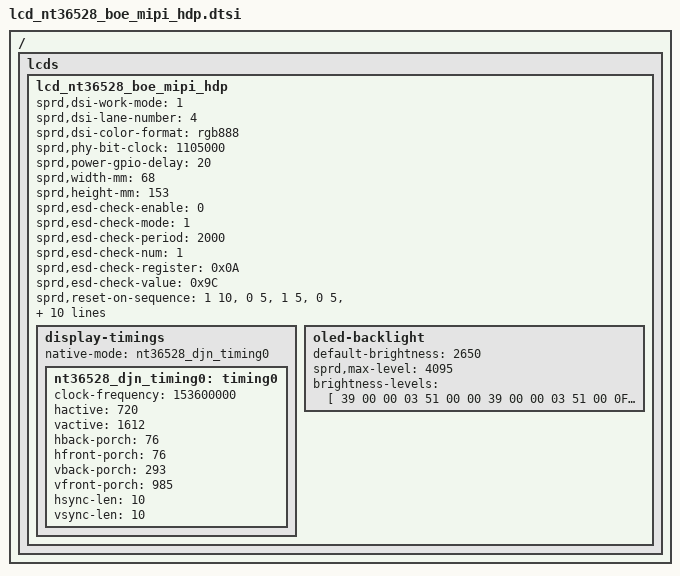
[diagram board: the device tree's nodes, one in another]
// SPDX-License-Identifier: GPL-2.0-only
/*
 * Unisoc ili9881c Truly LCD config DTS file
 *
 * Copyright (C) 2021, Unisoc Inc.
 */
/ {
	fragment {
		target-path = "/";
		__overlay__ {
			lcds {
				lcd_nt36528_boe_mipi_hdp: lcd_nt36528_boe_mipi_hdp {
					sprd,dsi-work-mode = <1>; /* video burst mode*/
					sprd,dsi-lane-number = <4>;
					sprd,dsi-color-format = "rgb888";

					sprd,phy-bit-clock = <1105000>; /* kbps */
					//sprd,phy-escape-clock = <20000>;/* kHz */
					//sprd,dpi-clk-div = <1>;
					sprd,power-gpio-delay = <20>;/* ms */

					//sprd,lcm_ic_name = "NT36528";
					//sprd,lcm_ic_vendor = "DJN";
					//sprd,lcm_ic_inch = "6.56";

					sprd,width-mm = <68>;
					sprd,height-mm = <153>;

					sprd,esd-check-enable = <0>;
					sprd,esd-check-mode = <1>;
					sprd,esd-check-period = <2000>;
					sprd,esd-check-num = <1>;
					sprd,esd-check-register = <0x0A>;
					sprd,esd-check-value = <0x9C>;

					sprd,reset-on-sequence = <1 10>, <0 5>, <1 5>, <0 5>, <1 20>;
					sprd,reset-off-sequence = <1 5>;

					sprd,initial-command = [
						23 00 00 02 FF 20
						23 00 00 02 FB 01
						23 00 00 02 07 B4
						23 00 00 02 08 B4
						23 00 00 02 0D 80
						23 00 00 02 1F 22
						23 00 00 02 82 66
						23 00 00 02 89 BE
						23 00 00 02 8B BE
						23 00 00 02 94 C0
						23 00 00 02 95 13
						23 00 00 02 96 13
						23 00 00 02 FF 24
						23 00 00 02 FB 01
						23 00 00 02 01 26
						23 00 00 02 02 21
						23 00 00 02 03 04
						23 00 00 02 04 05
						23 00 00 02 05 0C
						23 00 00 02 06 0D
						23 00 00 02 07 0E
						23 00 00 02 08 0F
						23 00 00 02 09 10
						23 00 00 02 0A 11
						23 00 00 02 0B 12
						23 00 00 02 0C 13
						23 00 00 02 0D 20
						23 00 00 02 17 26
						23 00 00 02 18 21
						23 00 00 02 19 04
						23 00 00 02 1A 05
						23 00 00 02 1B 0C
						23 00 00 02 1C 0D
						23 00 00 02 1D 0E
						23 00 00 02 1E 0F
						23 00 00 02 1F 10
						23 00 00 02 20 11
						23 00 00 02 21 12
						23 00 00 02 22 13
						23 00 00 02 23 20
						23 00 00 02 2F 11
						23 00 00 02 30 0D
						23 00 00 02 33 0D
						23 00 00 02 34 11
						23 00 00 02 37 88
						23 00 00 02 3A 06
						23 00 00 02 3B C8
						23 00 00 02 3D 52
						23 00 00 02 50 87
						23 00 00 02 51 78
						23 00 00 02 52 56
						23 00 00 02 53 34
						23 00 00 02 54 12
						39 00 00 03 55 4E 0E
						23 00 00 02 56 08
						23 00 00 02 5C 8A
						23 00 00 02 5D 0A
						39 00 00 03 5E 00 08
						23 00 00 02 AF 12
						23 00 00 02 B0 09
						23 00 00 02 B1 12
						23 00 00 02 B2 09
						23 00 00 02 FF 25
						23 00 00 02 FB 01
						23 00 00 02 44 06
						23 00 00 02 5D 06
						23 00 00 02 5E C8
						23 00 00 02 C0 8C
						23 00 00 02 C6 11
						23 00 00 02 FF 26
						23 00 00 02 FB 01
						23 00 00 02 4D 06
						23 00 00 02 4E 78
						23 00 00 02 6E 06
						23 00 00 02 6F 78
						23 00 00 02 7B 06
						23 00 00 02 7C 78
						23 00 00 02 FF 27
						23 00 00 02 FB 01
						23 00 00 02 14 66
						23 00 00 02 15 D8
						23 00 00 02 1A 66
						23 00 00 02 1B 66
						23 00 00 02 78 98
						23 00 00 02 79 0F
						23 00 00 02 7A 0F
						23 00 00 02 7C 0A
						23 00 00 02 7D 69
						23 00 00 02 7E 0A
						23 00 00 02 7F 69
						23 00 00 02 80 0A
						23 00 00 02 81 69
						23 00 00 02 83 12
						23 00 00 02 84 0E
						23 00 00 02 87 0E
						23 00 00 02 88 12
						23 00 00 02 93 80
						23 00 00 02 94 80
						23 00 00 02 96 0B
						23 00 00 02 97 15
						23 00 00 02 98 88
						23 00 00 02 C4 06
						23 00 00 02 C5 78
						23 00 00 02 C6 06
						23 00 00 02 C7 78
						23 00 00 02 E4 00
						23 00 00 02 E5 9D
						23 00 00 02 FF 2A
						23 00 00 02 FB 01
						23 00 00 02 64 96
						23 00 00 02 67 16
						23 00 00 02 6A 96
						23 00 00 02 73 9E
						23 00 00 02 76 9E
						23 00 00 02 79 16
						23 00 00 02 7C 16
						23 00 00 02 7F 96
						23 00 00 02 82 16
						23 00 00 02 85 16
						23 00 00 02 A2 3F
						23 00 00 02 A3 FF
						23 00 00 02 A4 C3
						23 00 00 02 FF 24
						23 00 00 02 FB 01
						23 00 00 02 59 70
						23 00 00 02 5A BC
						23 00 00 02 5B AA
						23 00 00 02 61 4C
						23 00 00 02 92 CE
						39 00 00 03 93 12 00
						23 00 00 02 94 C8
						23 00 00 02 DC C9
						23 00 00 02 E0 C9
						23 00 00 02 E2 C9
						23 00 00 02 E4 C9
						23 00 00 02 E6 C9
						23 00 00 02 EA C9
						23 00 00 02 EE C9
						23 00 00 02 F0 C9
						23 00 00 02 FF 25
						23 00 00 02 FB 01
						23 00 00 02 13 02
						23 00 00 02 14 72
						23 00 00 02 15 01
						23 00 00 02 16 8B
						23 00 00 02 1F BC
						23 00 00 02 20 AA
						23 00 00 02 26 BC
						23 00 00 02 27 AA
						23 00 00 02 48 BC
						23 00 00 02 49 AA
						23 00 00 02 50 BC
						23 00 00 02 51 AA
						23 00 00 02 61 BC
						23 00 00 02 62 AA
						23 00 00 02 68 08
						23 00 00 02 BC 24
						23 00 00 02 FF 26
						23 00 00 02 FB 01
						23 00 00 02 00 80
						23 00 00 02 02 0D
						23 00 00 02 04 2F
						23 00 00 02 09 05
						23 00 00 02 0A 05
						23 00 00 02 19 0B
						23 00 00 02 1A 54
						23 00 00 02 1B 0A
						23 00 00 02 1C C9
						23 00 00 02 1E CE
						23 00 00 02 1F CE
						23 00 00 02 24 00
						23 00 00 02 25 CE
						23 00 00 02 2A 0B
						23 00 00 02 2B 54
						23 00 00 02 2F 05
						23 00 00 02 30 CE
						23 00 00 02 32 CE
						23 00 00 02 37 11
						23 00 00 02 38 01
						23 00 00 02 39 08
						23 00 00 02 3A CE
						23 00 00 02 40 81
						23 00 00 02 41 81
						23 00 00 02 42 81
						23 00 00 02 44 81
						23 00 00 02 46 81
						23 00 00 02 48 81
						23 00 00 02 49 08
						23 00 00 02 4A 81
						23 00 00 02 51 7B
						23 00 00 02 52 69
						23 00 00 02 56 7B
						23 00 00 02 58 69
						23 00 00 02 5B 7B
						23 00 00 02 5C 69
						23 00 00 02 60 7B
						23 00 00 02 61 69
						23 00 00 02 64 7B
						23 00 00 02 65 69
						23 00 00 02 69 7B
						23 00 00 02 6A 69
						23 00 00 02 72 7B
						23 00 00 02 73 69
						23 00 00 02 8B 35
						23 00 00 02 8C 09
						23 00 00 02 8D 00
						23 00 00 02 99 0B
						23 00 00 02 9A 54
						23 00 00 02 9B 0A
						23 00 00 02 9C C9
						23 00 00 02 9D 0B
						23 00 00 02 9E 54
						23 00 00 02 C3 00
						23 00 00 02 FF 27
						23 00 00 02 FB 01
						23 00 00 02 58 A4
						39 00 00 03 59 00 12
						39 00 00 03 5A 00 C3
						39 00 00 03 5D 00 01
						39 00 00 03 5E 00 B1
						23 00 00 02 5F 01
						39 00 00 03 60 06 75
						23 00 00 02 C0 08
						23 00 00 02 F0 77
						23 00 00 02 F1 10
						23 00 00 02 F4 00
						23 00 00 02 F5 77
						23 00 00 02 FF 2A
						23 00 00 02 FB 01
						23 00 00 02 04 7C
						23 00 00 02 06 7C
						23 00 00 02 09 7C
						23 00 00 02 0B 7C
						23 00 00 02 0D 7C
						23 00 00 02 14 7C
						23 00 00 02 15 7C
						23 00 00 02 16 7C
						23 00 00 02 23 0C
						23 00 00 02 28 12
						23 00 00 02 2D 12
						23 00 00 02 33 12
						23 00 00 02 35 0A
						23 00 00 02 37 79
						23 00 00 02 99 95
						23 00 00 02 9A 0B
						23 00 00 02 C4 80
						23 00 00 02 C5 12
						23 00 00 02 C6 01
						23 00 00 02 C7 2A
						23 00 00 02 C8 10
						23 00 00 02 C9 01
						23 00 00 02 CA 18
						23 00 00 02 CB 16
						23 00 00 02 CC 75
						23 00 00 02 FF 23
						23 00 00 02 FB 01
						23 00 00 02 00 80
						23 00 00 02 07 00
						23 00 00 02 08 01
						23 00 00 02 09 1F
						23 00 00 02 11 00
						23 00 00 02 12 B5
						23 00 00 02 15 E7
						23 00 00 02 16 14
						23 00 00 02 FF 25
						23 00 00 02 FB 01
						39 00 00 05 02 00 40 00 40
						23 00 00 02 FF 27
						23 00 00 02 FB 01
						23 00 00 02 E9 02
						23 00 00 02 FF 2A
						23 00 00 02 FB 01
						23 00 00 02 99 95
						23 00 00 02 9A 0B
						23 00 00 02 AC 00
						23 00 00 02 AD 3C
						23 00 00 02 AE 80
						23 00 00 02 AF 43
						23 00 00 02 B0 18
						23 00 00 02 B1 90
						23 00 00 02 B3 22
						23 00 00 02 FF 10
						23 00 00 02 FB 01
						23 00 00 02 BA 03
						23 00 00 02 FF 25
						23 00 00 02 FB 01
						23 00 00 02 BC 24
						23 00 00 02 FF 26
						23 00 00 02 FB 01
						23 00 00 02 09 05
						23 00 00 02 FF 2A
						23 00 00 02 FB 01
						23 00 00 02 23 0C
						23 00 00 02 FF 10
						23 00 00 02 FB 01
						23 00 00 02 55 00
						23 00 00 02 53 2C
						39 00 00 03 51 00 00
						23 00 00 02 35 00
						13 78 00 01 11
						13 14 00 01 29
						];

					sprd,sleep-in-command = [
						13 14 00 01 28
						13 78 00 01 10
						];

					sprd,sleep-out-command = [
						13 78 00 01 11
						13 14 00 01 29
						];

					sprd,oled-backlight-close = [
						39 00 00 03 51 00 00
						];

					display-timings {
						native-mode = <&nt36528_djn_timing0>;

						nt36528_djn_timing0: timing0 {
							clock-frequency = <153600000>;
							hactive = <720>;
							vactive = <1612>;
							hback-porch = <76>;
							hfront-porch = <76>;
							vback-porch = <293>;
							vfront-porch = <985>;
							hsync-len = <10>;
							vsync-len = <10>;
						};
						//nt36528_djn_timing1: timing1 {
						//	clock-frequency = <153600000>;
						//	hactive = <720>;
						//	vactive = <1612>;
						//	hback-porch = <76>;
						//	hfront-porch = <76>;
						//	vback-porch = <293>;
						//	vfront-porch = <18>;
						//	hsync-len = <10>;
						//	vsync-len = <10>;
						//};
					};

					oled-backlight {
						default-brightness = <2650>;
						sprd,max-level = <4095>;

						brightness-levels = [
							39 00 00 03 51 00 00
							39 00 00 03 51 00 0F
							39 00 00 03 51 00 0F
							39 00 00 03 51 00 0F
							39 00 00 03 51 00 0F
							39 00 00 03 51 00 0F
							39 00 00 03 51 00 0F
							39 00 00 03 51 00 0F
							39 00 00 03 51 00 0F
							39 00 00 03 51 00 0F
							39 00 00 03 51 00 0F
							39 00 00 03 51 00 0F
							39 00 00 03 51 00 0F
							39 00 00 03 51 00 0F
							39 00 00 03 51 00 0F
							39 00 00 03 51 00 0F
							39 00 00 03 51 00 10
							39 00 00 03 51 00 11
							39 00 00 03 51 00 12
							39 00 00 03 51 00 13
							39 00 00 03 51 00 14
							39 00 00 03 51 00 15
							39 00 00 03 51 00 16
							39 00 00 03 51 00 17
							39 00 00 03 51 00 18
							39 00 00 03 51 00 19
							39 00 00 03 51 00 1A
							39 00 00 03 51 00 1B
							39 00 00 03 51 00 1C
							39 00 00 03 51 00 1D
							39 00 00 03 51 00 1E
							39 00 00 03 51 00 1F
							39 00 00 03 51 00 20
							39 00 00 03 51 00 21
							39 00 00 03 51 00 22
							39 00 00 03 51 00 23
							39 00 00 03 51 00 24
							39 00 00 03 51 00 25
							39 00 00 03 51 00 26
							39 00 00 03 51 00 27
							39 00 00 03 51 00 28
							39 00 00 03 51 00 29
							39 00 00 03 51 00 2A
							39 00 00 03 51 00 2B
							39 00 00 03 51 00 2C
							39 00 00 03 51 00 2D
							39 00 00 03 51 00 2E
							39 00 00 03 51 00 2F
							39 00 00 03 51 00 30
							39 00 00 03 51 00 31
							39 00 00 03 51 00 32
							39 00 00 03 51 00 33
							39 00 00 03 51 00 34
							39 00 00 03 51 00 35
							39 00 00 03 51 00 36
							39 00 00 03 51 00 37
							39 00 00 03 51 00 38
							39 00 00 03 51 00 39
							39 00 00 03 51 00 3A
							39 00 00 03 51 00 3B
							39 00 00 03 51 00 3C
							39 00 00 03 51 00 3D
							39 00 00 03 51 00 3E
							39 00 00 03 51 00 3F
							39 00 00 03 51 00 40
							39 00 00 03 51 00 41
							39 00 00 03 51 00 42
							39 00 00 03 51 00 43
							39 00 00 03 51 00 44
							39 00 00 03 51 00 45
							39 00 00 03 51 00 46
							39 00 00 03 51 00 47
							39 00 00 03 51 00 48
							39 00 00 03 51 00 49
							39 00 00 03 51 00 4A
							39 00 00 03 51 00 4B
							39 00 00 03 51 00 4C
							39 00 00 03 51 00 4D
							39 00 00 03 51 00 4E
							39 00 00 03 51 00 4F
							39 00 00 03 51 00 50
							39 00 00 03 51 00 51
							39 00 00 03 51 00 52
							39 00 00 03 51 00 53
							39 00 00 03 51 00 54
							39 00 00 03 51 00 55
							39 00 00 03 51 00 56
							39 00 00 03 51 00 57
							39 00 00 03 51 00 58
							39 00 00 03 51 00 59
							39 00 00 03 51 00 5A
							39 00 00 03 51 00 5B
							39 00 00 03 51 00 5C
							39 00 00 03 51 00 5D
							39 00 00 03 51 00 5E
							39 00 00 03 51 00 5F
							39 00 00 03 51 00 60
							39 00 00 03 51 00 61
							39 00 00 03 51 00 62
							39 00 00 03 51 00 63
							39 00 00 03 51 00 64
							39 00 00 03 51 00 65
							39 00 00 03 51 00 66
							39 00 00 03 51 00 67
							39 00 00 03 51 00 68
							39 00 00 03 51 00 69
							39 00 00 03 51 00 6A
							39 00 00 03 51 00 6B
							39 00 00 03 51 00 6C
							39 00 00 03 51 00 6D
							39 00 00 03 51 00 6E
							39 00 00 03 51 00 6F
							39 00 00 03 51 00 70
							39 00 00 03 51 00 71
							39 00 00 03 51 00 72
							39 00 00 03 51 00 73
							39 00 00 03 51 00 74
							39 00 00 03 51 00 75
							39 00 00 03 51 00 76
							39 00 00 03 51 00 77
							39 00 00 03 51 00 78
							39 00 00 03 51 00 79
							39 00 00 03 51 00 7A
							39 00 00 03 51 00 7B
							39 00 00 03 51 00 7C
							39 00 00 03 51 00 7D
							39 00 00 03 51 00 7E
							39 00 00 03 51 00 7F
							39 00 00 03 51 00 80
							39 00 00 03 51 00 81
							39 00 00 03 51 00 82
							39 00 00 03 51 00 83
							39 00 00 03 51 00 84
							39 00 00 03 51 00 85
							39 00 00 03 51 00 86
							39 00 00 03 51 00 87
							39 00 00 03 51 00 88
							39 00 00 03 51 00 89
							39 00 00 03 51 00 8A
							39 00 00 03 51 00 8B
							39 00 00 03 51 00 8C
							39 00 00 03 51 00 8D
							39 00 00 03 51 00 8E
							39 00 00 03 51 00 8F
							39 00 00 03 51 00 90
							39 00 00 03 51 00 91
							39 00 00 03 51 00 92
							39 00 00 03 51 00 93
							39 00 00 03 51 00 94
							39 00 00 03 51 00 95
							39 00 00 03 51 00 96
							39 00 00 03 51 00 97
							39 00 00 03 51 00 98
							39 00 00 03 51 00 99
							39 00 00 03 51 00 9A
							39 00 00 03 51 00 9B
							39 00 00 03 51 00 9C
							39 00 00 03 51 00 9D
							39 00 00 03 51 00 9E
							39 00 00 03 51 00 9F
							39 00 00 03 51 00 A0
							39 00 00 03 51 00 A1
							39 00 00 03 51 00 A2
							39 00 00 03 51 00 A3
							39 00 00 03 51 00 A4
							39 00 00 03 51 00 A5
							39 00 00 03 51 00 A6
							39 00 00 03 51 00 A7
							39 00 00 03 51 00 A8
							39 00 00 03 51 00 A9
							39 00 00 03 51 00 AA
							39 00 00 03 51 00 AB
							39 00 00 03 51 00 AC
							39 00 00 03 51 00 AD
							39 00 00 03 51 00 AE
							39 00 00 03 51 00 AF
							39 00 00 03 51 00 B0
							39 00 00 03 51 00 B1
							39 00 00 03 51 00 B2
							39 00 00 03 51 00 B3
							39 00 00 03 51 00 B4
							39 00 00 03 51 00 B5
							39 00 00 03 51 00 B6
							39 00 00 03 51 00 B7
							39 00 00 03 51 00 B8
							39 00 00 03 51 00 B9
							39 00 00 03 51 00 BA
							39 00 00 03 51 00 BB
							39 00 00 03 51 00 BC
							39 00 00 03 51 00 BD
							39 00 00 03 51 00 BE
							39 00 00 03 51 00 BF
							39 00 00 03 51 00 C0
							39 00 00 03 51 00 C1
							39 00 00 03 51 00 C2
							39 00 00 03 51 00 C3
							39 00 00 03 51 00 C4
							39 00 00 03 51 00 C5
							39 00 00 03 51 00 C6
							39 00 00 03 51 00 C7
							39 00 00 03 51 00 C8
							39 00 00 03 51 00 C9
							39 00 00 03 51 00 CA
							39 00 00 03 51 00 CB
							39 00 00 03 51 00 CC
							39 00 00 03 51 00 CD
							39 00 00 03 51 00 CE
							39 00 00 03 51 00 CF
							39 00 00 03 51 00 D0
							39 00 00 03 51 00 D1
							39 00 00 03 51 00 D2
							39 00 00 03 51 00 D3
							39 00 00 03 51 00 D4
							39 00 00 03 51 00 D5
							39 00 00 03 51 00 D6
							39 00 00 03 51 00 D7
							39 00 00 03 51 00 D8
							39 00 00 03 51 00 D9
							39 00 00 03 51 00 DA
							39 00 00 03 51 00 DB
							39 00 00 03 51 00 DC
							39 00 00 03 51 00 DD
							39 00 00 03 51 00 DE
							39 00 00 03 51 00 DF
							39 00 00 03 51 00 E0
							39 00 00 03 51 00 E1
							39 00 00 03 51 00 E2
							39 00 00 03 51 00 E3
							39 00 00 03 51 00 E4
							39 00 00 03 51 00 E5
							39 00 00 03 51 00 E6
							39 00 00 03 51 00 E7
							39 00 00 03 51 00 E8
							39 00 00 03 51 00 E9
							39 00 00 03 51 00 EA
							39 00 00 03 51 00 EB
							39 00 00 03 51 00 EC
							39 00 00 03 51 00 ED
							39 00 00 03 51 00 EE
							39 00 00 03 51 00 EF
							39 00 00 03 51 00 F0
							39 00 00 03 51 00 F1
							39 00 00 03 51 00 F2
							39 00 00 03 51 00 F3
							39 00 00 03 51 00 F4
							39 00 00 03 51 00 F5
							39 00 00 03 51 00 F6
							39 00 00 03 51 00 F7
							39 00 00 03 51 00 F8
							39 00 00 03 51 00 F9
							39 00 00 03 51 00 FA
							39 00 00 03 51 00 FB
							39 00 00 03 51 00 FC
							39 00 00 03 51 00 FD
							39 00 00 03 51 00 FE
							39 00 00 03 51 00 FF
							39 00 00 03 51 01 00
							39 00 00 03 51 01 01
							39 00 00 03 51 01 02
							39 00 00 03 51 01 03
							39 00 00 03 51 01 04
							39 00 00 03 51 01 05
							39 00 00 03 51 01 06
							39 00 00 03 51 01 07
							39 00 00 03 51 01 08
							39 00 00 03 51 01 09
							39 00 00 03 51 01 0A
							39 00 00 03 51 01 0B
							39 00 00 03 51 01 0C
							39 00 00 03 51 01 0D
							39 00 00 03 51 01 0E
							39 00 00 03 51 01 0F
							39 00 00 03 51 01 10
							39 00 00 03 51 01 11
							39 00 00 03 51 01 12
							39 00 00 03 51 01 13
							39 00 00 03 51 01 14
							39 00 00 03 51 01 15
							39 00 00 03 51 01 16
							39 00 00 03 51 01 17
							39 00 00 03 51 01 18
							39 00 00 03 51 01 19
							39 00 00 03 51 01 1A
							39 00 00 03 51 01 1B
							39 00 00 03 51 01 1C
							39 00 00 03 51 01 1D
							39 00 00 03 51 01 1E
							39 00 00 03 51 01 1F
							39 00 00 03 51 01 20
							39 00 00 03 51 01 21
							39 00 00 03 51 01 22
							39 00 00 03 51 01 23
							39 00 00 03 51 01 24
							39 00 00 03 51 01 25
							39 00 00 03 51 01 26
							39 00 00 03 51 01 27
							39 00 00 03 51 01 28
							39 00 00 03 51 01 29
							39 00 00 03 51 01 2A
							39 00 00 03 51 01 2B
							39 00 00 03 51 01 2C
							39 00 00 03 51 01 2D
							39 00 00 03 51 01 2E
							39 00 00 03 51 01 2F
							39 00 00 03 51 01 30
							39 00 00 03 51 01 31
							39 00 00 03 51 01 32
							39 00 00 03 51 01 33
							39 00 00 03 51 01 34
							39 00 00 03 51 01 35
							39 00 00 03 51 01 36
							39 00 00 03 51 01 37
							39 00 00 03 51 01 38
							39 00 00 03 51 01 39
							39 00 00 03 51 01 3A
							39 00 00 03 51 01 3B
							39 00 00 03 51 01 3C
							39 00 00 03 51 01 3D
							39 00 00 03 51 01 3E
							39 00 00 03 51 01 3F
							39 00 00 03 51 01 40
							39 00 00 03 51 01 41
							39 00 00 03 51 01 42
							39 00 00 03 51 01 43
							39 00 00 03 51 01 44
							39 00 00 03 51 01 45
							39 00 00 03 51 01 46
							39 00 00 03 51 01 47
							39 00 00 03 51 01 48
							39 00 00 03 51 01 49
							39 00 00 03 51 01 4A
							39 00 00 03 51 01 4B
							39 00 00 03 51 01 4C
							39 00 00 03 51 01 4D
							39 00 00 03 51 01 4E
							39 00 00 03 51 01 4F
							39 00 00 03 51 01 50
							39 00 00 03 51 01 51
							39 00 00 03 51 01 52
							39 00 00 03 51 01 53
							39 00 00 03 51 01 54
							39 00 00 03 51 01 55
							39 00 00 03 51 01 56
							39 00 00 03 51 01 57
							39 00 00 03 51 01 58
							39 00 00 03 51 01 59
							39 00 00 03 51 01 5A
							39 00 00 03 51 01 5B
							39 00 00 03 51 01 5C
							39 00 00 03 51 01 5D
							39 00 00 03 51 01 5E
							39 00 00 03 51 01 5F
							39 00 00 03 51 01 60
							39 00 00 03 51 01 61
							39 00 00 03 51 01 62
							39 00 00 03 51 01 63
							39 00 00 03 51 01 64
							39 00 00 03 51 01 65
							39 00 00 03 51 01 66
							39 00 00 03 51 01 67
							39 00 00 03 51 01 68
							39 00 00 03 51 01 69
							39 00 00 03 51 01 6A
							39 00 00 03 51 01 6B
							39 00 00 03 51 01 6C
							39 00 00 03 51 01 6D
							39 00 00 03 51 01 6E
							39 00 00 03 51 01 6F
							39 00 00 03 51 01 70
							39 00 00 03 51 01 71
							39 00 00 03 51 01 72
							39 00 00 03 51 01 73
							39 00 00 03 51 01 74
							39 00 00 03 51 01 75
							39 00 00 03 51 01 76
							39 00 00 03 51 01 77
							39 00 00 03 51 01 78
							39 00 00 03 51 01 79
							39 00 00 03 51 01 7A
							39 00 00 03 51 01 7B
							39 00 00 03 51 01 7C
							39 00 00 03 51 01 7D
							39 00 00 03 51 01 7E
							39 00 00 03 51 01 7F
							39 00 00 03 51 01 80
							39 00 00 03 51 01 81
							39 00 00 03 51 01 82
							39 00 00 03 51 01 83
							39 00 00 03 51 01 84
							39 00 00 03 51 01 85
							39 00 00 03 51 01 86
							39 00 00 03 51 01 87
							39 00 00 03 51 01 88
							39 00 00 03 51 01 89
							39 00 00 03 51 01 8A
							39 00 00 03 51 01 8B
							39 00 00 03 51 01 8C
							39 00 00 03 51 01 8D
							39 00 00 03 51 01 8E
							39 00 00 03 51 01 8F
							39 00 00 03 51 01 90
							39 00 00 03 51 01 91
							39 00 00 03 51 01 92
							39 00 00 03 51 01 93
							39 00 00 03 51 01 94
							39 00 00 03 51 01 95
							39 00 00 03 51 01 96
							39 00 00 03 51 01 97
							39 00 00 03 51 01 98
							39 00 00 03 51 01 99
							39 00 00 03 51 01 9A
							39 00 00 03 51 01 9B
							39 00 00 03 51 01 9C
							39 00 00 03 51 01 9D
							39 00 00 03 51 01 9E
							39 00 00 03 51 01 9F
							39 00 00 03 51 01 A0
							39 00 00 03 51 01 A1
							39 00 00 03 51 01 A2
							39 00 00 03 51 01 A3
							39 00 00 03 51 01 A4
							39 00 00 03 51 01 A5
							39 00 00 03 51 01 A6
							39 00 00 03 51 01 A7
							39 00 00 03 51 01 A8
							39 00 00 03 51 01 A9
							39 00 00 03 51 01 AA
							39 00 00 03 51 01 AB
							39 00 00 03 51 01 AC
							39 00 00 03 51 01 AD
							39 00 00 03 51 01 AE
							39 00 00 03 51 01 AF
							39 00 00 03 51 01 B0
							39 00 00 03 51 01 B1
							39 00 00 03 51 01 B2
							39 00 00 03 51 01 B3
							39 00 00 03 51 01 B4
							39 00 00 03 51 01 B5
							39 00 00 03 51 01 B6
							39 00 00 03 51 01 B7
							39 00 00 03 51 01 B8
							39 00 00 03 51 01 B9
							39 00 00 03 51 01 BA
							39 00 00 03 51 01 BB
							39 00 00 03 51 01 BC
							39 00 00 03 51 01 BD
							39 00 00 03 51 01 BE
							39 00 00 03 51 01 BF
							39 00 00 03 51 01 C0
							39 00 00 03 51 01 C1
							39 00 00 03 51 01 C2
							39 00 00 03 51 01 C3
							39 00 00 03 51 01 C4
							39 00 00 03 51 01 C5
							39 00 00 03 51 01 C6
							39 00 00 03 51 01 C7
							39 00 00 03 51 01 C8
							39 00 00 03 51 01 C9
							39 00 00 03 51 01 CA
							39 00 00 03 51 01 CB
							39 00 00 03 51 01 CC
							39 00 00 03 51 01 CD
							39 00 00 03 51 01 CE
							39 00 00 03 51 01 CF
							39 00 00 03 51 01 D0
							39 00 00 03 51 01 D1
							39 00 00 03 51 01 D2
							39 00 00 03 51 01 D3
							39 00 00 03 51 01 D4
							39 00 00 03 51 01 D5
							39 00 00 03 51 01 D6
							39 00 00 03 51 01 D7
							39 00 00 03 51 01 D8
							39 00 00 03 51 01 D9
							39 00 00 03 51 01 DA
							39 00 00 03 51 01 DB
							39 00 00 03 51 01 DC
							39 00 00 03 51 01 DD
							39 00 00 03 51 01 DE
							39 00 00 03 51 01 DF
							39 00 00 03 51 01 E0
							39 00 00 03 51 01 E1
							39 00 00 03 51 01 E2
							39 00 00 03 51 01 E3
							39 00 00 03 51 01 E4
							39 00 00 03 51 01 E5
							39 00 00 03 51 01 E6
							39 00 00 03 51 01 E7
							39 00 00 03 51 01 E8
							39 00 00 03 51 01 E9
							39 00 00 03 51 01 EA
							39 00 00 03 51 01 EB
							39 00 00 03 51 01 EC
							39 00 00 03 51 01 ED
							39 00 00 03 51 01 EE
							39 00 00 03 51 01 EF
							39 00 00 03 51 01 F0
							39 00 00 03 51 01 F1
							39 00 00 03 51 01 F2
							39 00 00 03 51 01 F3
							39 00 00 03 51 01 F4
							39 00 00 03 51 01 F5
							39 00 00 03 51 01 F6
							39 00 00 03 51 01 F7
							39 00 00 03 51 01 F8
							39 00 00 03 51 01 F9
							39 00 00 03 51 01 FA
							39 00 00 03 51 01 FB
							39 00 00 03 51 01 FC
							39 00 00 03 51 01 FD
							39 00 00 03 51 01 FE
							39 00 00 03 51 01 FF
							39 00 00 03 51 02 00
							39 00 00 03 51 02 01
							39 00 00 03 51 02 02
							39 00 00 03 51 02 03
							39 00 00 03 51 02 04
							39 00 00 03 51 02 05
							39 00 00 03 51 02 06
							39 00 00 03 51 02 07
							39 00 00 03 51 02 08
							39 00 00 03 51 02 09
							39 00 00 03 51 02 0A
							39 00 00 03 51 02 0B
							39 00 00 03 51 02 0C
							39 00 00 03 51 02 0D
							39 00 00 03 51 02 0E
							39 00 00 03 51 02 0F
							39 00 00 03 51 02 10
							39 00 00 03 51 02 11
							39 00 00 03 51 02 12
							39 00 00 03 51 02 13
							39 00 00 03 51 02 14
							39 00 00 03 51 02 15
							39 00 00 03 51 02 16
							39 00 00 03 51 02 17
							39 00 00 03 51 02 18
							39 00 00 03 51 02 19
							39 00 00 03 51 02 1A
							39 00 00 03 51 02 1B
							39 00 00 03 51 02 1C
							39 00 00 03 51 02 1D
							39 00 00 03 51 02 1E
							39 00 00 03 51 02 1F
							39 00 00 03 51 02 20
							39 00 00 03 51 02 21
							39 00 00 03 51 02 22
							39 00 00 03 51 02 23
							39 00 00 03 51 02 24
							39 00 00 03 51 02 25
							39 00 00 03 51 02 26
							39 00 00 03 51 02 27
							39 00 00 03 51 02 28
							39 00 00 03 51 02 29
							39 00 00 03 51 02 2A
							39 00 00 03 51 02 2B
							39 00 00 03 51 02 2C
							39 00 00 03 51 02 2D
							39 00 00 03 51 02 2E
							39 00 00 03 51 02 2F
							39 00 00 03 51 02 30
							39 00 00 03 51 02 31
							39 00 00 03 51 02 32
							39 00 00 03 51 02 33
							39 00 00 03 51 02 34
							39 00 00 03 51 02 35
							39 00 00 03 51 02 36
							39 00 00 03 51 02 37
							39 00 00 03 51 02 38
							39 00 00 03 51 02 39
							39 00 00 03 51 02 3A
							39 00 00 03 51 02 3B
							39 00 00 03 51 02 3C
							39 00 00 03 51 02 3D
							39 00 00 03 51 02 3E
							39 00 00 03 51 02 3F
							39 00 00 03 51 02 40
							39 00 00 03 51 02 41
							39 00 00 03 51 02 42
							39 00 00 03 51 02 43
							39 00 00 03 51 02 44
							39 00 00 03 51 02 45
							39 00 00 03 51 02 46
							39 00 00 03 51 02 47
							39 00 00 03 51 02 48
							39 00 00 03 51 02 49
							39 00 00 03 51 02 4A
							39 00 00 03 51 02 4B
							39 00 00 03 51 02 4C
							39 00 00 03 51 02 4D
							39 00 00 03 51 02 4E
							39 00 00 03 51 02 4F
							39 00 00 03 51 02 50
							39 00 00 03 51 02 51
							39 00 00 03 51 02 52
							39 00 00 03 51 02 53
							39 00 00 03 51 02 54
							39 00 00 03 51 02 55
							39 00 00 03 51 02 56
							39 00 00 03 51 02 57
							39 00 00 03 51 02 58
							39 00 00 03 51 02 59
							39 00 00 03 51 02 5A
							39 00 00 03 51 02 5B
							39 00 00 03 51 02 5C
							39 00 00 03 51 02 5D
							39 00 00 03 51 02 5E
							39 00 00 03 51 02 5F
							39 00 00 03 51 02 60
							39 00 00 03 51 02 61
							39 00 00 03 51 02 62
							39 00 00 03 51 02 63
							39 00 00 03 51 02 64
							39 00 00 03 51 02 65
							39 00 00 03 51 02 66
							39 00 00 03 51 02 67
							39 00 00 03 51 02 68
							39 00 00 03 51 02 69
							39 00 00 03 51 02 6A
							39 00 00 03 51 02 6B
							39 00 00 03 51 02 6C
							39 00 00 03 51 02 6D
							39 00 00 03 51 02 6E
							39 00 00 03 51 02 6F
							39 00 00 03 51 02 70
							39 00 00 03 51 02 71
							39 00 00 03 51 02 72
							39 00 00 03 51 02 73
							39 00 00 03 51 02 74
							39 00 00 03 51 02 75
							39 00 00 03 51 02 76
							39 00 00 03 51 02 77
							39 00 00 03 51 02 78
							39 00 00 03 51 02 79
							39 00 00 03 51 02 7A
							39 00 00 03 51 02 7B
							39 00 00 03 51 02 7C
							39 00 00 03 51 02 7D
							39 00 00 03 51 02 7E
							39 00 00 03 51 02 7F
							39 00 00 03 51 02 80
							39 00 00 03 51 02 81
							39 00 00 03 51 02 82
							39 00 00 03 51 02 83
							39 00 00 03 51 02 84
							39 00 00 03 51 02 85
							39 00 00 03 51 02 86
							39 00 00 03 51 02 87
							39 00 00 03 51 02 88
							39 00 00 03 51 02 89
							39 00 00 03 51 02 8A
							39 00 00 03 51 02 8B
							39 00 00 03 51 02 8C
							39 00 00 03 51 02 8D
							39 00 00 03 51 02 8E
							39 00 00 03 51 02 8F
							39 00 00 03 51 02 90
							39 00 00 03 51 02 91
							39 00 00 03 51 02 92
							39 00 00 03 51 02 93
							39 00 00 03 51 02 94
							39 00 00 03 51 02 95
							39 00 00 03 51 02 96
							39 00 00 03 51 02 97
							39 00 00 03 51 02 98
							39 00 00 03 51 02 99
							39 00 00 03 51 02 9A
							39 00 00 03 51 02 9B
							39 00 00 03 51 02 9C
							39 00 00 03 51 02 9D
							39 00 00 03 51 02 9E
							39 00 00 03 51 02 9F
							39 00 00 03 51 02 A0
							39 00 00 03 51 02 A1
							39 00 00 03 51 02 A2
							39 00 00 03 51 02 A3
							39 00 00 03 51 02 A4
							39 00 00 03 51 02 A5
							39 00 00 03 51 02 A6
							39 00 00 03 51 02 A7
							39 00 00 03 51 02 A8
							39 00 00 03 51 02 A9
							39 00 00 03 51 02 AA
							39 00 00 03 51 02 AB
							39 00 00 03 51 02 AC
							39 00 00 03 51 02 AD
							39 00 00 03 51 02 AE
							39 00 00 03 51 02 AF
							39 00 00 03 51 02 B0
							39 00 00 03 51 02 B1
							39 00 00 03 51 02 B2
							39 00 00 03 51 02 B3
							39 00 00 03 51 02 B4
							39 00 00 03 51 02 B5
							39 00 00 03 51 02 B6
							39 00 00 03 51 02 B7
							39 00 00 03 51 02 B8
							39 00 00 03 51 02 B9
							39 00 00 03 51 02 BA
							39 00 00 03 51 02 BB
							39 00 00 03 51 02 BC
							39 00 00 03 51 02 BD
							39 00 00 03 51 02 BE
							39 00 00 03 51 02 BF
							39 00 00 03 51 02 C0
							39 00 00 03 51 02 C1
							39 00 00 03 51 02 C2
							39 00 00 03 51 02 C3
							39 00 00 03 51 02 C4
							39 00 00 03 51 02 C5
							39 00 00 03 51 02 C6
							39 00 00 03 51 02 C7
							39 00 00 03 51 02 C8
							39 00 00 03 51 02 C9
							39 00 00 03 51 02 CA
							39 00 00 03 51 02 CB
							39 00 00 03 51 02 CC
							39 00 00 03 51 02 CD
							39 00 00 03 51 02 CE
							39 00 00 03 51 02 CF
							39 00 00 03 51 02 D0
							39 00 00 03 51 02 D1
							39 00 00 03 51 02 D2
							39 00 00 03 51 02 D3
							39 00 00 03 51 02 D4
							39 00 00 03 51 02 D5
							39 00 00 03 51 02 D6
							39 00 00 03 51 02 D7
							39 00 00 03 51 02 D8
							39 00 00 03 51 02 D9
							39 00 00 03 51 02 DA
							39 00 00 03 51 02 DB
							39 00 00 03 51 02 DC
							39 00 00 03 51 02 DD
							39 00 00 03 51 02 DE
							39 00 00 03 51 02 DF
							39 00 00 03 51 02 E0
							39 00 00 03 51 02 E1
							39 00 00 03 51 02 E2
							39 00 00 03 51 02 E3
							39 00 00 03 51 02 E4
							39 00 00 03 51 02 E5
							39 00 00 03 51 02 E6
							39 00 00 03 51 02 E7
							39 00 00 03 51 02 E8
							39 00 00 03 51 02 E9
							39 00 00 03 51 02 EA
							39 00 00 03 51 02 EB
							39 00 00 03 51 02 EC
							39 00 00 03 51 02 ED
							39 00 00 03 51 02 EE
							39 00 00 03 51 02 EF
							39 00 00 03 51 02 F0
							39 00 00 03 51 02 F1
							39 00 00 03 51 02 F2
							39 00 00 03 51 02 F3
							39 00 00 03 51 02 F4
							39 00 00 03 51 02 F5
							39 00 00 03 51 02 F6
							39 00 00 03 51 02 F7
							39 00 00 03 51 02 F8
							39 00 00 03 51 02 F9
							39 00 00 03 51 02 FA
							39 00 00 03 51 02 FB
							39 00 00 03 51 02 FC
							39 00 00 03 51 02 FD
							39 00 00 03 51 02 FE
							39 00 00 03 51 02 FF
							39 00 00 03 51 03 00
							39 00 00 03 51 03 01
							39 00 00 03 51 03 02
							39 00 00 03 51 03 03
							39 00 00 03 51 03 04
							39 00 00 03 51 03 05
							39 00 00 03 51 03 06
							39 00 00 03 51 03 07
							39 00 00 03 51 03 08
							39 00 00 03 51 03 09
							39 00 00 03 51 03 0A
							39 00 00 03 51 03 0B
							39 00 00 03 51 03 0C
							39 00 00 03 51 03 0D
							39 00 00 03 51 03 0E
							39 00 00 03 51 03 0F
							39 00 00 03 51 03 10
							39 00 00 03 51 03 11
							39 00 00 03 51 03 12
							39 00 00 03 51 03 13
							39 00 00 03 51 03 14
							39 00 00 03 51 03 15
							39 00 00 03 51 03 16
							39 00 00 03 51 03 17
							39 00 00 03 51 03 18
							39 00 00 03 51 03 19
							39 00 00 03 51 03 1A
							39 00 00 03 51 03 1B
							39 00 00 03 51 03 1C
							39 00 00 03 51 03 1D
							39 00 00 03 51 03 1E
							39 00 00 03 51 03 1F
							39 00 00 03 51 03 20
							39 00 00 03 51 03 21
							39 00 00 03 51 03 22
							39 00 00 03 51 03 23
							39 00 00 03 51 03 24
							39 00 00 03 51 03 25
							39 00 00 03 51 03 26
							39 00 00 03 51 03 27
							39 00 00 03 51 03 28
							39 00 00 03 51 03 29
							39 00 00 03 51 03 2A
							39 00 00 03 51 03 2B
							39 00 00 03 51 03 2C
							39 00 00 03 51 03 2D
							39 00 00 03 51 03 2E
							39 00 00 03 51 03 2F
							39 00 00 03 51 03 30
							39 00 00 03 51 03 31
							39 00 00 03 51 03 32
							39 00 00 03 51 03 33
							39 00 00 03 51 03 34
							39 00 00 03 51 03 35
							39 00 00 03 51 03 36
							39 00 00 03 51 03 37
							39 00 00 03 51 03 38
							39 00 00 03 51 03 39
							39 00 00 03 51 03 3A
							39 00 00 03 51 03 3B
							39 00 00 03 51 03 3C
							39 00 00 03 51 03 3D
							39 00 00 03 51 03 3E
							39 00 00 03 51 03 3F
							39 00 00 03 51 03 40
							39 00 00 03 51 03 41
							39 00 00 03 51 03 42
							39 00 00 03 51 03 43
							39 00 00 03 51 03 44
							39 00 00 03 51 03 45
							39 00 00 03 51 03 46
							39 00 00 03 51 03 47
							39 00 00 03 51 03 48
							39 00 00 03 51 03 49
							39 00 00 03 51 03 4A
							39 00 00 03 51 03 4B
							39 00 00 03 51 03 4C
							39 00 00 03 51 03 4D
							39 00 00 03 51 03 4E
							39 00 00 03 51 03 4F
							39 00 00 03 51 03 50
							39 00 00 03 51 03 51
							39 00 00 03 51 03 52
							39 00 00 03 51 03 53
							39 00 00 03 51 03 54
							39 00 00 03 51 03 55
							39 00 00 03 51 03 56
							39 00 00 03 51 03 57
							39 00 00 03 51 03 58
							39 00 00 03 51 03 59
							39 00 00 03 51 03 5A
							39 00 00 03 51 03 5B
							39 00 00 03 51 03 5C
							39 00 00 03 51 03 5D
							39 00 00 03 51 03 5E
							39 00 00 03 51 03 5F
							39 00 00 03 51 03 60
							39 00 00 03 51 03 61
							39 00 00 03 51 03 62
							39 00 00 03 51 03 63
							39 00 00 03 51 03 64
							39 00 00 03 51 03 65
							39 00 00 03 51 03 66
							39 00 00 03 51 03 67
							39 00 00 03 51 03 68
							39 00 00 03 51 03 69
							39 00 00 03 51 03 6A
							39 00 00 03 51 03 6B
							39 00 00 03 51 03 6C
							39 00 00 03 51 03 6D
							39 00 00 03 51 03 6E
							39 00 00 03 51 03 6F
							39 00 00 03 51 03 70
							39 00 00 03 51 03 71
							39 00 00 03 51 03 72
							39 00 00 03 51 03 73
							39 00 00 03 51 03 74
							39 00 00 03 51 03 75
							39 00 00 03 51 03 76
							39 00 00 03 51 03 77
							39 00 00 03 51 03 78
							39 00 00 03 51 03 79
							39 00 00 03 51 03 7A
							39 00 00 03 51 03 7B
							39 00 00 03 51 03 7C
							39 00 00 03 51 03 7D
							39 00 00 03 51 03 7E
							39 00 00 03 51 03 7F
							39 00 00 03 51 03 80
							39 00 00 03 51 03 81
							39 00 00 03 51 03 82
							39 00 00 03 51 03 83
							39 00 00 03 51 03 84
							39 00 00 03 51 03 85
							39 00 00 03 51 03 86
							39 00 00 03 51 03 87
							39 00 00 03 51 03 88
							39 00 00 03 51 03 89
							39 00 00 03 51 03 8A
							39 00 00 03 51 03 8B
							39 00 00 03 51 03 8C
							39 00 00 03 51 03 8D
							39 00 00 03 51 03 8E
							39 00 00 03 51 03 8F
							39 00 00 03 51 03 90
							39 00 00 03 51 03 91
							39 00 00 03 51 03 92
							39 00 00 03 51 03 93
							39 00 00 03 51 03 94
							39 00 00 03 51 03 95
							39 00 00 03 51 03 96
							39 00 00 03 51 03 97
							39 00 00 03 51 03 98
							39 00 00 03 51 03 99
							39 00 00 03 51 03 9A
							39 00 00 03 51 03 9B
							39 00 00 03 51 03 9C
							39 00 00 03 51 03 9D
							39 00 00 03 51 03 9E
							39 00 00 03 51 03 9F
							39 00 00 03 51 03 A0
							39 00 00 03 51 03 A1
							39 00 00 03 51 03 A2
							39 00 00 03 51 03 A3
							39 00 00 03 51 03 A4
							39 00 00 03 51 03 A5
							39 00 00 03 51 03 A6
							39 00 00 03 51 03 A7
							39 00 00 03 51 03 A8
							39 00 00 03 51 03 A9
							39 00 00 03 51 03 AA
							39 00 00 03 51 03 AB
							39 00 00 03 51 03 AC
							39 00 00 03 51 03 AD
							39 00 00 03 51 03 AE
							39 00 00 03 51 03 AF
							39 00 00 03 51 03 B0
							39 00 00 03 51 03 B1
							39 00 00 03 51 03 B2
							39 00 00 03 51 03 B3
							39 00 00 03 51 03 B4
							39 00 00 03 51 03 B5
							39 00 00 03 51 03 B6
							39 00 00 03 51 03 B7
							39 00 00 03 51 03 B8
							39 00 00 03 51 03 B9
							39 00 00 03 51 03 BA
							39 00 00 03 51 03 BB
							39 00 00 03 51 03 BC
							39 00 00 03 51 03 BD
							39 00 00 03 51 03 BE
							39 00 00 03 51 03 BF
							39 00 00 03 51 03 C0
							39 00 00 03 51 03 C1
							39 00 00 03 51 03 C2
							39 00 00 03 51 03 C3
							39 00 00 03 51 03 C4
							39 00 00 03 51 03 C5
							39 00 00 03 51 03 C6
							39 00 00 03 51 03 C7
							39 00 00 03 51 03 C8
							39 00 00 03 51 03 C9
							39 00 00 03 51 03 CA
							39 00 00 03 51 03 CB
							39 00 00 03 51 03 CC
							39 00 00 03 51 03 CD
							39 00 00 03 51 03 CE
							39 00 00 03 51 03 CF
							39 00 00 03 51 03 D0
							39 00 00 03 51 03 D1
							39 00 00 03 51 03 D2
							39 00 00 03 51 03 D3
							39 00 00 03 51 03 D4
							39 00 00 03 51 03 D5
							39 00 00 03 51 03 D6
							39 00 00 03 51 03 D7
							39 00 00 03 51 03 D8
							39 00 00 03 51 03 D9
							39 00 00 03 51 03 DA
							39 00 00 03 51 03 DB
							39 00 00 03 51 03 DC
							39 00 00 03 51 03 DD
							39 00 00 03 51 03 DE
							39 00 00 03 51 03 DF
							39 00 00 03 51 03 E0
							39 00 00 03 51 03 E1
							39 00 00 03 51 03 E2
							39 00 00 03 51 03 E3
							39 00 00 03 51 03 E4
							39 00 00 03 51 03 E5
							39 00 00 03 51 03 E6
							39 00 00 03 51 03 E7
							39 00 00 03 51 03 E8
							39 00 00 03 51 03 E9
							39 00 00 03 51 03 EA
							39 00 00 03 51 03 EB
							39 00 00 03 51 03 EC
							39 00 00 03 51 03 ED
							39 00 00 03 51 03 EE
							39 00 00 03 51 03 EF
							39 00 00 03 51 03 F0
							39 00 00 03 51 03 F1
							39 00 00 03 51 03 F2
							39 00 00 03 51 03 F3
							39 00 00 03 51 03 F4
							39 00 00 03 51 03 F5
							39 00 00 03 51 03 F6
							39 00 00 03 51 03 F7
							39 00 00 03 51 03 F8
							39 00 00 03 51 03 F9
							39 00 00 03 51 03 FA
							39 00 00 03 51 03 FB
							39 00 00 03 51 03 FC
							39 00 00 03 51 03 FD
							39 00 00 03 51 03 FE
							39 00 00 03 51 03 FF
							39 00 00 03 51 04 00
							39 00 00 03 51 04 01
							39 00 00 03 51 04 02
							39 00 00 03 51 04 03
							39 00 00 03 51 04 04
							39 00 00 03 51 04 05
							39 00 00 03 51 04 06
							39 00 00 03 51 04 07
							39 00 00 03 51 04 08
							39 00 00 03 51 04 09
							39 00 00 03 51 04 0A
							39 00 00 03 51 04 0B
							39 00 00 03 51 04 0C
							39 00 00 03 51 04 0D
							39 00 00 03 51 04 0E
							39 00 00 03 51 04 0F
							39 00 00 03 51 04 10
							39 00 00 03 51 04 11
							39 00 00 03 51 04 12
							39 00 00 03 51 04 13
							39 00 00 03 51 04 14
							39 00 00 03 51 04 15
							39 00 00 03 51 04 16
							39 00 00 03 51 04 17
							39 00 00 03 51 04 18
							39 00 00 03 51 04 19
							39 00 00 03 51 04 1A
							39 00 00 03 51 04 1B
							39 00 00 03 51 04 1C
							39 00 00 03 51 04 1D
							39 00 00 03 51 04 1E
							39 00 00 03 51 04 1F
							39 00 00 03 51 04 20
							39 00 00 03 51 04 21
							39 00 00 03 51 04 22
							39 00 00 03 51 04 23
							39 00 00 03 51 04 24
							39 00 00 03 51 04 25
							39 00 00 03 51 04 26
							39 00 00 03 51 04 27
							39 00 00 03 51 04 28
							39 00 00 03 51 04 29
							39 00 00 03 51 04 2A
							39 00 00 03 51 04 2B
							39 00 00 03 51 04 2C
							39 00 00 03 51 04 2D
							39 00 00 03 51 04 2E
							39 00 00 03 51 04 2F
							39 00 00 03 51 04 30
							39 00 00 03 51 04 31
							39 00 00 03 51 04 32
							39 00 00 03 51 04 33
							39 00 00 03 51 04 34
							39 00 00 03 51 04 35
							39 00 00 03 51 04 36
							39 00 00 03 51 04 37
							39 00 00 03 51 04 38
							39 00 00 03 51 04 39
							39 00 00 03 51 04 3A
							39 00 00 03 51 04 3B
							39 00 00 03 51 04 3C
							39 00 00 03 51 04 3D
							39 00 00 03 51 04 3E
							39 00 00 03 51 04 3F
							39 00 00 03 51 04 40
							39 00 00 03 51 04 41
							39 00 00 03 51 04 42
							39 00 00 03 51 04 43
							39 00 00 03 51 04 44
							39 00 00 03 51 04 45
							39 00 00 03 51 04 46
							39 00 00 03 51 04 47
							39 00 00 03 51 04 48
							39 00 00 03 51 04 49
							39 00 00 03 51 04 4A
							39 00 00 03 51 04 4B
							39 00 00 03 51 04 4C
							39 00 00 03 51 04 4D
							39 00 00 03 51 04 4E
							39 00 00 03 51 04 4F
							39 00 00 03 51 04 50
							39 00 00 03 51 04 51
							39 00 00 03 51 04 52
							39 00 00 03 51 04 53
							39 00 00 03 51 04 54
							39 00 00 03 51 04 55
							39 00 00 03 51 04 56
							39 00 00 03 51 04 57
							39 00 00 03 51 04 58
							39 00 00 03 51 04 59
							39 00 00 03 51 04 5A
							39 00 00 03 51 04 5B
							39 00 00 03 51 04 5C
							39 00 00 03 51 04 5D
							39 00 00 03 51 04 5E
							39 00 00 03 51 04 5F
							39 00 00 03 51 04 60
							39 00 00 03 51 04 61
							39 00 00 03 51 04 62
							39 00 00 03 51 04 63
							39 00 00 03 51 04 64
							39 00 00 03 51 04 65
							39 00 00 03 51 04 66
							39 00 00 03 51 04 67
							39 00 00 03 51 04 68
							39 00 00 03 51 04 69
							39 00 00 03 51 04 6A
							39 00 00 03 51 04 6B
							39 00 00 03 51 04 6C
							39 00 00 03 51 04 6D
							39 00 00 03 51 04 6E
							39 00 00 03 51 04 6F
							39 00 00 03 51 04 70
							39 00 00 03 51 04 71
							39 00 00 03 51 04 72
							39 00 00 03 51 04 73
							39 00 00 03 51 04 74
							39 00 00 03 51 04 75
							39 00 00 03 51 04 76
							39 00 00 03 51 04 77
							39 00 00 03 51 04 78
							39 00 00 03 51 04 79
							39 00 00 03 51 04 7A
							39 00 00 03 51 04 7B
							39 00 00 03 51 04 7C
							39 00 00 03 51 04 7D
							39 00 00 03 51 04 7E
							39 00 00 03 51 04 7F
							39 00 00 03 51 04 80
							39 00 00 03 51 04 81
							39 00 00 03 51 04 82
							39 00 00 03 51 04 83
							39 00 00 03 51 04 84
							39 00 00 03 51 04 85
							39 00 00 03 51 04 86
							39 00 00 03 51 04 87
							39 00 00 03 51 04 88
							39 00 00 03 51 04 89
							39 00 00 03 51 04 8A
							39 00 00 03 51 04 8B
							39 00 00 03 51 04 8C
							39 00 00 03 51 04 8D
							39 00 00 03 51 04 8E
							39 00 00 03 51 04 8F
							39 00 00 03 51 04 90
							39 00 00 03 51 04 91
							39 00 00 03 51 04 92
							39 00 00 03 51 04 93
							39 00 00 03 51 04 94
							39 00 00 03 51 04 95
							39 00 00 03 51 04 96
							39 00 00 03 51 04 97
							39 00 00 03 51 04 98
							39 00 00 03 51 04 99
							39 00 00 03 51 04 9A
							39 00 00 03 51 04 9B
							39 00 00 03 51 04 9C
							39 00 00 03 51 04 9D
							39 00 00 03 51 04 9E
							39 00 00 03 51 04 9F
							39 00 00 03 51 04 A0
							39 00 00 03 51 04 A1
							39 00 00 03 51 04 A2
							39 00 00 03 51 04 A3
							39 00 00 03 51 04 A4
							39 00 00 03 51 04 A5
							39 00 00 03 51 04 A6
							39 00 00 03 51 04 A7
							39 00 00 03 51 04 A8
							39 00 00 03 51 04 A9
							39 00 00 03 51 04 AA
							39 00 00 03 51 04 AB
							39 00 00 03 51 04 AC
							39 00 00 03 51 04 AD
							39 00 00 03 51 04 AE
							39 00 00 03 51 04 AF
							39 00 00 03 51 04 B0
							39 00 00 03 51 04 B1
							39 00 00 03 51 04 B2
							39 00 00 03 51 04 B3
							39 00 00 03 51 04 B4
							39 00 00 03 51 04 B5
							39 00 00 03 51 04 B6
							39 00 00 03 51 04 B7
							39 00 00 03 51 04 B8
							39 00 00 03 51 04 B9
							39 00 00 03 51 04 BA
							39 00 00 03 51 04 BB
							39 00 00 03 51 04 BC
							39 00 00 03 51 04 BD
							39 00 00 03 51 04 BE
							39 00 00 03 51 04 BF
							39 00 00 03 51 04 C0
							39 00 00 03 51 04 C1
							39 00 00 03 51 04 C2
							39 00 00 03 51 04 C3
							39 00 00 03 51 04 C4
							39 00 00 03 51 04 C5
							39 00 00 03 51 04 C6
							39 00 00 03 51 04 C7
							39 00 00 03 51 04 C8
							39 00 00 03 51 04 C9
							39 00 00 03 51 04 CA
							39 00 00 03 51 04 CB
							39 00 00 03 51 04 CC
							39 00 00 03 51 04 CD
							39 00 00 03 51 04 CE
							39 00 00 03 51 04 CF
							39 00 00 03 51 04 D0
							39 00 00 03 51 04 D1
							39 00 00 03 51 04 D2
							39 00 00 03 51 04 D3
							39 00 00 03 51 04 D4
							39 00 00 03 51 04 D5
							39 00 00 03 51 04 D6
							39 00 00 03 51 04 D7
							39 00 00 03 51 04 D8
							39 00 00 03 51 04 D9
							39 00 00 03 51 04 DA
							39 00 00 03 51 04 DB
							39 00 00 03 51 04 DC
							39 00 00 03 51 04 DD
							39 00 00 03 51 04 DE
							39 00 00 03 51 04 DF
							39 00 00 03 51 04 E0
							39 00 00 03 51 04 E1
							39 00 00 03 51 04 E2
							39 00 00 03 51 04 E3
							39 00 00 03 51 04 E4
							39 00 00 03 51 04 E5
							39 00 00 03 51 04 E6
							39 00 00 03 51 04 E7
							39 00 00 03 51 04 E8
							39 00 00 03 51 04 E9
							39 00 00 03 51 04 EA
							39 00 00 03 51 04 EB
							39 00 00 03 51 04 EC
							39 00 00 03 51 04 ED
							39 00 00 03 51 04 EE
							39 00 00 03 51 04 EF
							39 00 00 03 51 04 F0
							39 00 00 03 51 04 F1
							39 00 00 03 51 04 F2
							39 00 00 03 51 04 F3
							39 00 00 03 51 04 F4
							39 00 00 03 51 04 F5
							39 00 00 03 51 04 F6
							39 00 00 03 51 04 F7
							39 00 00 03 51 04 F8
							39 00 00 03 51 04 F9
							39 00 00 03 51 04 FA
							39 00 00 03 51 04 FB
							39 00 00 03 51 04 FC
							39 00 00 03 51 04 FD
							39 00 00 03 51 04 FE
							39 00 00 03 51 04 FF
							39 00 00 03 51 05 00
							39 00 00 03 51 05 01
							39 00 00 03 51 05 02
							39 00 00 03 51 05 03
							39 00 00 03 51 05 04
							39 00 00 03 51 05 05
							39 00 00 03 51 05 06
							39 00 00 03 51 05 07
							39 00 00 03 51 05 08
							39 00 00 03 51 05 09
							39 00 00 03 51 05 0A
							39 00 00 03 51 05 0B
							39 00 00 03 51 05 0C
							39 00 00 03 51 05 0D
							39 00 00 03 51 05 0E
							39 00 00 03 51 05 0F
							39 00 00 03 51 05 10
							39 00 00 03 51 05 11
							39 00 00 03 51 05 12
							39 00 00 03 51 05 13
							39 00 00 03 51 05 14
							39 00 00 03 51 05 15
							39 00 00 03 51 05 16
							39 00 00 03 51 05 17
							39 00 00 03 51 05 18
							39 00 00 03 51 05 19
							39 00 00 03 51 05 1A
							39 00 00 03 51 05 1B
							39 00 00 03 51 05 1C
							39 00 00 03 51 05 1D
							39 00 00 03 51 05 1E
							39 00 00 03 51 05 1F
							39 00 00 03 51 05 20
							39 00 00 03 51 05 21
							39 00 00 03 51 05 22
							39 00 00 03 51 05 23
							39 00 00 03 51 05 24
							39 00 00 03 51 05 25
							39 00 00 03 51 05 26
							39 00 00 03 51 05 27
							39 00 00 03 51 05 28
							39 00 00 03 51 05 29
							39 00 00 03 51 05 2A
							39 00 00 03 51 05 2B
							39 00 00 03 51 05 2C
							39 00 00 03 51 05 2D
							39 00 00 03 51 05 2E
							39 00 00 03 51 05 2F
							39 00 00 03 51 05 30
							39 00 00 03 51 05 31
							39 00 00 03 51 05 32
							39 00 00 03 51 05 33
							39 00 00 03 51 05 34
							39 00 00 03 51 05 35
							39 00 00 03 51 05 36
							39 00 00 03 51 05 37
							39 00 00 03 51 05 38
							39 00 00 03 51 05 39
							39 00 00 03 51 05 3A
							39 00 00 03 51 05 3B
							39 00 00 03 51 05 3C
							39 00 00 03 51 05 3D
							39 00 00 03 51 05 3E
							39 00 00 03 51 05 3F
							39 00 00 03 51 05 40
							39 00 00 03 51 05 41
							39 00 00 03 51 05 42
							39 00 00 03 51 05 43
							39 00 00 03 51 05 44
							39 00 00 03 51 05 45
							39 00 00 03 51 05 46
							39 00 00 03 51 05 47
							39 00 00 03 51 05 48
							39 00 00 03 51 05 49
							39 00 00 03 51 05 4A
							39 00 00 03 51 05 4B
							39 00 00 03 51 05 4C
							39 00 00 03 51 05 4D
							39 00 00 03 51 05 4E
							39 00 00 03 51 05 4F
							39 00 00 03 51 05 50
							39 00 00 03 51 05 51
							39 00 00 03 51 05 52
							39 00 00 03 51 05 53
							39 00 00 03 51 05 54
							39 00 00 03 51 05 55
							39 00 00 03 51 05 56
							39 00 00 03 51 05 57
							39 00 00 03 51 05 58
							39 00 00 03 51 05 59
							39 00 00 03 51 05 5A
							39 00 00 03 51 05 5B
							39 00 00 03 51 05 5C
							39 00 00 03 51 05 5D
							39 00 00 03 51 05 5E
							39 00 00 03 51 05 5F
							39 00 00 03 51 05 60
							39 00 00 03 51 05 61
							39 00 00 03 51 05 62
							39 00 00 03 51 05 63
							39 00 00 03 51 05 64
							39 00 00 03 51 05 65
							39 00 00 03 51 05 66
							39 00 00 03 51 05 67
							39 00 00 03 51 05 68
							39 00 00 03 51 05 69
							39 00 00 03 51 05 6A
							39 00 00 03 51 05 6B
							39 00 00 03 51 05 6C
							39 00 00 03 51 05 6D
							39 00 00 03 51 05 6E
							39 00 00 03 51 05 6F
							39 00 00 03 51 05 70
							39 00 00 03 51 05 71
							39 00 00 03 51 05 72
							39 00 00 03 51 05 73
							39 00 00 03 51 05 74
							39 00 00 03 51 05 75
							39 00 00 03 51 05 76
							39 00 00 03 51 05 77
							39 00 00 03 51 05 78
							39 00 00 03 51 05 79
							39 00 00 03 51 05 7A
							39 00 00 03 51 05 7B
							39 00 00 03 51 05 7C
							39 00 00 03 51 05 7D
							39 00 00 03 51 05 7E
							39 00 00 03 51 05 7F
							39 00 00 03 51 05 80
							39 00 00 03 51 05 81
							39 00 00 03 51 05 82
							39 00 00 03 51 05 83
							39 00 00 03 51 05 84
							39 00 00 03 51 05 85
							39 00 00 03 51 05 86
							39 00 00 03 51 05 87
							39 00 00 03 51 05 88
							39 00 00 03 51 05 89
							39 00 00 03 51 05 8A
							39 00 00 03 51 05 8B
							39 00 00 03 51 05 8C
							39 00 00 03 51 05 8D
							39 00 00 03 51 05 8E
							39 00 00 03 51 05 8F
							39 00 00 03 51 05 90
							39 00 00 03 51 05 91
							39 00 00 03 51 05 92
							39 00 00 03 51 05 93
							39 00 00 03 51 05 94
							39 00 00 03 51 05 95
							39 00 00 03 51 05 96
							39 00 00 03 51 05 97
							39 00 00 03 51 05 98
							39 00 00 03 51 05 99
							39 00 00 03 51 05 9A
							39 00 00 03 51 05 9B
							39 00 00 03 51 05 9C
							39 00 00 03 51 05 9D
							39 00 00 03 51 05 9E
							39 00 00 03 51 05 9F
							39 00 00 03 51 05 A0
							39 00 00 03 51 05 A1
							39 00 00 03 51 05 A2
							39 00 00 03 51 05 A3
							39 00 00 03 51 05 A4
							39 00 00 03 51 05 A5
							39 00 00 03 51 05 A6
							39 00 00 03 51 05 A7
							39 00 00 03 51 05 A8
							39 00 00 03 51 05 A9
							39 00 00 03 51 05 AA
							39 00 00 03 51 05 AB
							39 00 00 03 51 05 AC
							39 00 00 03 51 05 AD
							39 00 00 03 51 05 AE
							39 00 00 03 51 05 AF
							39 00 00 03 51 05 B0
							39 00 00 03 51 05 B1
							39 00 00 03 51 05 B2
							39 00 00 03 51 05 B3
							39 00 00 03 51 05 B4
							39 00 00 03 51 05 B5
							39 00 00 03 51 05 B6
							39 00 00 03 51 05 B7
							39 00 00 03 51 05 B8
							39 00 00 03 51 05 B9
							39 00 00 03 51 05 BA
							39 00 00 03 51 05 BB
							39 00 00 03 51 05 BC
							39 00 00 03 51 05 BD
							39 00 00 03 51 05 BE
							39 00 00 03 51 05 BF
							39 00 00 03 51 05 C0
							39 00 00 03 51 05 C1
							39 00 00 03 51 05 C2
							39 00 00 03 51 05 C3
							39 00 00 03 51 05 C4
							39 00 00 03 51 05 C5
							39 00 00 03 51 05 C6
							39 00 00 03 51 05 C7
							39 00 00 03 51 05 C8
							39 00 00 03 51 05 C9
							39 00 00 03 51 05 CA
							39 00 00 03 51 05 CB
							39 00 00 03 51 05 CC
							39 00 00 03 51 05 CD
							39 00 00 03 51 05 CE
							39 00 00 03 51 05 CF
							39 00 00 03 51 05 D0
							39 00 00 03 51 05 D1
							39 00 00 03 51 05 D2
							39 00 00 03 51 05 D3
							39 00 00 03 51 05 D4
							39 00 00 03 51 05 D5
							39 00 00 03 51 05 D6
							39 00 00 03 51 05 D7
							39 00 00 03 51 05 D8
							39 00 00 03 51 05 D9
							39 00 00 03 51 05 DA
							39 00 00 03 51 05 DB
							39 00 00 03 51 05 DC
							39 00 00 03 51 05 DD
							39 00 00 03 51 05 DE
							39 00 00 03 51 05 DF
							39 00 00 03 51 05 E0
							39 00 00 03 51 05 E1
							39 00 00 03 51 05 E2
							39 00 00 03 51 05 E3
							39 00 00 03 51 05 E4
							39 00 00 03 51 05 E5
							39 00 00 03 51 05 E6
							39 00 00 03 51 05 E7
							39 00 00 03 51 05 E8
							39 00 00 03 51 05 E9
							39 00 00 03 51 05 EA
							39 00 00 03 51 05 EB
							39 00 00 03 51 05 EC
							39 00 00 03 51 05 ED
							39 00 00 03 51 05 EE
							39 00 00 03 51 05 EF
							39 00 00 03 51 05 F0
							39 00 00 03 51 05 F1
							39 00 00 03 51 05 F2
							39 00 00 03 51 05 F3
							39 00 00 03 51 05 F4
							39 00 00 03 51 05 F5
							39 00 00 03 51 05 F6
							39 00 00 03 51 05 F7
							39 00 00 03 51 05 F8
							39 00 00 03 51 05 F9
							39 00 00 03 51 05 FA
							39 00 00 03 51 05 FB
							39 00 00 03 51 05 FC
							39 00 00 03 51 05 FD
							39 00 00 03 51 05 FE
							39 00 00 03 51 05 FF
							39 00 00 03 51 06 00
							39 00 00 03 51 06 01
							39 00 00 03 51 06 02
							39 00 00 03 51 06 03
							39 00 00 03 51 06 04
							39 00 00 03 51 06 05
							39 00 00 03 51 06 06
							39 00 00 03 51 06 07
							39 00 00 03 51 06 08
							39 00 00 03 51 06 09
							39 00 00 03 51 06 0A
							39 00 00 03 51 06 0B
							39 00 00 03 51 06 0C
							39 00 00 03 51 06 0D
							39 00 00 03 51 06 0E
							39 00 00 03 51 06 0F
							39 00 00 03 51 06 10
							39 00 00 03 51 06 11
							39 00 00 03 51 06 12
							39 00 00 03 51 06 13
							39 00 00 03 51 06 14
							39 00 00 03 51 06 15
							39 00 00 03 51 06 16
							39 00 00 03 51 06 17
							39 00 00 03 51 06 18
							39 00 00 03 51 06 19
							39 00 00 03 51 06 1A
							39 00 00 03 51 06 1B
							39 00 00 03 51 06 1C
							39 00 00 03 51 06 1D
							39 00 00 03 51 06 1E
							39 00 00 03 51 06 1F
							39 00 00 03 51 06 20
							39 00 00 03 51 06 21
							39 00 00 03 51 06 22
							39 00 00 03 51 06 23
							39 00 00 03 51 06 24
							39 00 00 03 51 06 25
							39 00 00 03 51 06 26
							39 00 00 03 51 06 27
							39 00 00 03 51 06 28
							39 00 00 03 51 06 29
							39 00 00 03 51 06 2A
							39 00 00 03 51 06 2B
							39 00 00 03 51 06 2C
							39 00 00 03 51 06 2D
							39 00 00 03 51 06 2E
							39 00 00 03 51 06 2F
							39 00 00 03 51 06 30
							39 00 00 03 51 06 31
							39 00 00 03 51 06 32
							39 00 00 03 51 06 33
							39 00 00 03 51 06 34
							39 00 00 03 51 06 35
							39 00 00 03 51 06 36
							39 00 00 03 51 06 37
							39 00 00 03 51 06 38
							39 00 00 03 51 06 39
							39 00 00 03 51 06 3A
							39 00 00 03 51 06 3B
							39 00 00 03 51 06 3C
							39 00 00 03 51 06 3D
							39 00 00 03 51 06 3E
							39 00 00 03 51 06 3F
							39 00 00 03 51 06 40
							39 00 00 03 51 06 41
							39 00 00 03 51 06 42
							39 00 00 03 51 06 43
							39 00 00 03 51 06 44
							39 00 00 03 51 06 45
							39 00 00 03 51 06 46
							39 00 00 03 51 06 47
							39 00 00 03 51 06 48
							39 00 00 03 51 06 49
							39 00 00 03 51 06 4A
							39 00 00 03 51 06 4B
							39 00 00 03 51 06 4C
							39 00 00 03 51 06 4D
							39 00 00 03 51 06 4E
							39 00 00 03 51 06 4F
							39 00 00 03 51 06 50
							39 00 00 03 51 06 51
							39 00 00 03 51 06 52
							39 00 00 03 51 06 53
							39 00 00 03 51 06 54
							39 00 00 03 51 06 55
							39 00 00 03 51 06 56
							39 00 00 03 51 06 57
							39 00 00 03 51 06 58
							39 00 00 03 51 06 59
							39 00 00 03 51 06 5A
							39 00 00 03 51 06 5B
							39 00 00 03 51 06 5C
							39 00 00 03 51 06 5D
							39 00 00 03 51 06 5E
							39 00 00 03 51 06 5F
							39 00 00 03 51 06 60
							39 00 00 03 51 06 61
							39 00 00 03 51 06 62
							39 00 00 03 51 06 63
							39 00 00 03 51 06 64
							39 00 00 03 51 06 65
							39 00 00 03 51 06 66
							39 00 00 03 51 06 67
							39 00 00 03 51 06 68
							39 00 00 03 51 06 69
							39 00 00 03 51 06 6A
							39 00 00 03 51 06 6B
							39 00 00 03 51 06 6C
							39 00 00 03 51 06 6D
							39 00 00 03 51 06 6E
							39 00 00 03 51 06 6F
							39 00 00 03 51 06 70
							39 00 00 03 51 06 71
							39 00 00 03 51 06 72
							39 00 00 03 51 06 73
							39 00 00 03 51 06 74
							39 00 00 03 51 06 75
							39 00 00 03 51 06 76
							39 00 00 03 51 06 77
							39 00 00 03 51 06 78
							39 00 00 03 51 06 79
							39 00 00 03 51 06 7A
							39 00 00 03 51 06 7B
							39 00 00 03 51 06 7C
							39 00 00 03 51 06 7D
							39 00 00 03 51 06 7E
							39 00 00 03 51 06 7F
							39 00 00 03 51 06 80
							39 00 00 03 51 06 81
							39 00 00 03 51 06 82
							39 00 00 03 51 06 83
							39 00 00 03 51 06 84
							39 00 00 03 51 06 85
							39 00 00 03 51 06 86
							39 00 00 03 51 06 87
							39 00 00 03 51 06 88
							39 00 00 03 51 06 89
							39 00 00 03 51 06 8A
							39 00 00 03 51 06 8B
							39 00 00 03 51 06 8C
							39 00 00 03 51 06 8D
							39 00 00 03 51 06 8E
							39 00 00 03 51 06 8F
							39 00 00 03 51 06 90
							39 00 00 03 51 06 91
							39 00 00 03 51 06 92
							39 00 00 03 51 06 93
							39 00 00 03 51 06 94
							39 00 00 03 51 06 95
							39 00 00 03 51 06 96
							39 00 00 03 51 06 97
							39 00 00 03 51 06 98
							39 00 00 03 51 06 99
							39 00 00 03 51 06 9A
							39 00 00 03 51 06 9B
							39 00 00 03 51 06 9C
							39 00 00 03 51 06 9D
							39 00 00 03 51 06 9E
							39 00 00 03 51 06 9F
							39 00 00 03 51 06 A0
							39 00 00 03 51 06 A1
							39 00 00 03 51 06 A2
							39 00 00 03 51 06 A3
							39 00 00 03 51 06 A4
							39 00 00 03 51 06 A5
							39 00 00 03 51 06 A6
							39 00 00 03 51 06 A7
							39 00 00 03 51 06 A8
							39 00 00 03 51 06 A9
							39 00 00 03 51 06 AA
							39 00 00 03 51 06 AB
							39 00 00 03 51 06 AC
							39 00 00 03 51 06 AD
							39 00 00 03 51 06 AE
							39 00 00 03 51 06 AF
							39 00 00 03 51 06 B0
							39 00 00 03 51 06 B1
							39 00 00 03 51 06 B2
							39 00 00 03 51 06 B3
							39 00 00 03 51 06 B4
							39 00 00 03 51 06 B5
							39 00 00 03 51 06 B6
							39 00 00 03 51 06 B7
							39 00 00 03 51 06 B8
							39 00 00 03 51 06 B9
							39 00 00 03 51 06 BA
							39 00 00 03 51 06 BB
							39 00 00 03 51 06 BC
							39 00 00 03 51 06 BD
							39 00 00 03 51 06 BE
							39 00 00 03 51 06 BF
							39 00 00 03 51 06 C0
							39 00 00 03 51 06 C1
							39 00 00 03 51 06 C2
							39 00 00 03 51 06 C3
							39 00 00 03 51 06 C4
							39 00 00 03 51 06 C5
							39 00 00 03 51 06 C6
							39 00 00 03 51 06 C7
							39 00 00 03 51 06 C8
							39 00 00 03 51 06 C9
							39 00 00 03 51 06 CA
							39 00 00 03 51 06 CB
							39 00 00 03 51 06 CC
							39 00 00 03 51 06 CD
							39 00 00 03 51 06 CE
							39 00 00 03 51 06 CF
							39 00 00 03 51 06 D0
							39 00 00 03 51 06 D1
							39 00 00 03 51 06 D2
							39 00 00 03 51 06 D3
							39 00 00 03 51 06 D4
							39 00 00 03 51 06 D5
							39 00 00 03 51 06 D6
							39 00 00 03 51 06 D7
							39 00 00 03 51 06 D8
							39 00 00 03 51 06 D9
							39 00 00 03 51 06 DA
							39 00 00 03 51 06 DB
							39 00 00 03 51 06 DC
							39 00 00 03 51 06 DD
							39 00 00 03 51 06 DE
							39 00 00 03 51 06 DF
							39 00 00 03 51 06 E0
							39 00 00 03 51 06 E1
							39 00 00 03 51 06 E2
							39 00 00 03 51 06 E3
							39 00 00 03 51 06 E4
							39 00 00 03 51 06 E5
							39 00 00 03 51 06 E6
							39 00 00 03 51 06 E7
							39 00 00 03 51 06 E8
							39 00 00 03 51 06 E9
							39 00 00 03 51 06 EA
							39 00 00 03 51 06 EB
							39 00 00 03 51 06 EC
							39 00 00 03 51 06 ED
							39 00 00 03 51 06 EE
							39 00 00 03 51 06 EF
							39 00 00 03 51 06 F0
							39 00 00 03 51 06 F1
							39 00 00 03 51 06 F2
							39 00 00 03 51 06 F3
							39 00 00 03 51 06 F4
							39 00 00 03 51 06 F5
							39 00 00 03 51 06 F6
							39 00 00 03 51 06 F7
							39 00 00 03 51 06 F8
							39 00 00 03 51 06 F9
							39 00 00 03 51 06 FA
							39 00 00 03 51 06 FB
							39 00 00 03 51 06 FC
							39 00 00 03 51 06 FD
							39 00 00 03 51 06 FE
							39 00 00 03 51 06 FF
							39 00 00 03 51 07 00
							39 00 00 03 51 07 01
							39 00 00 03 51 07 02
							39 00 00 03 51 07 03
							39 00 00 03 51 07 04
							39 00 00 03 51 07 05
							39 00 00 03 51 07 06
							39 00 00 03 51 07 07
							39 00 00 03 51 07 08
							39 00 00 03 51 07 09
							39 00 00 03 51 07 0A
							39 00 00 03 51 07 0B
							39 00 00 03 51 07 0C
							39 00 00 03 51 07 0D
							39 00 00 03 51 07 0E
							39 00 00 03 51 07 0F
							39 00 00 03 51 07 10
							39 00 00 03 51 07 11
							39 00 00 03 51 07 12
							39 00 00 03 51 07 13
							39 00 00 03 51 07 14
							39 00 00 03 51 07 15
							39 00 00 03 51 07 16
							39 00 00 03 51 07 17
							39 00 00 03 51 07 18
							39 00 00 03 51 07 19
							39 00 00 03 51 07 1A
							39 00 00 03 51 07 1B
							39 00 00 03 51 07 1C
							39 00 00 03 51 07 1D
							39 00 00 03 51 07 1E
							39 00 00 03 51 07 1F
							39 00 00 03 51 07 20
							39 00 00 03 51 07 21
							39 00 00 03 51 07 22
							39 00 00 03 51 07 23
							39 00 00 03 51 07 24
							39 00 00 03 51 07 25
							39 00 00 03 51 07 26
							39 00 00 03 51 07 27
							39 00 00 03 51 07 28
							39 00 00 03 51 07 29
							39 00 00 03 51 07 2A
							39 00 00 03 51 07 2B
							39 00 00 03 51 07 2C
							39 00 00 03 51 07 2D
							39 00 00 03 51 07 2E
							39 00 00 03 51 07 2F
							39 00 00 03 51 07 30
							39 00 00 03 51 07 31
							39 00 00 03 51 07 32
							39 00 00 03 51 07 33
							39 00 00 03 51 07 34
							39 00 00 03 51 07 35
							39 00 00 03 51 07 36
							39 00 00 03 51 07 37
							39 00 00 03 51 07 38
							39 00 00 03 51 07 39
							39 00 00 03 51 07 3A
							39 00 00 03 51 07 3B
							39 00 00 03 51 07 3C
							39 00 00 03 51 07 3D
							39 00 00 03 51 07 3E
							39 00 00 03 51 07 3F
							39 00 00 03 51 07 40
							39 00 00 03 51 07 41
							39 00 00 03 51 07 42
							39 00 00 03 51 07 43
							39 00 00 03 51 07 44
							39 00 00 03 51 07 45
							39 00 00 03 51 07 46
							39 00 00 03 51 07 47
							39 00 00 03 51 07 48
							39 00 00 03 51 07 49
							39 00 00 03 51 07 4A
							39 00 00 03 51 07 4B
							39 00 00 03 51 07 4C
							39 00 00 03 51 07 4D
							39 00 00 03 51 07 4E
							39 00 00 03 51 07 4F
							39 00 00 03 51 07 50
							39 00 00 03 51 07 51
							39 00 00 03 51 07 52
							39 00 00 03 51 07 53
							39 00 00 03 51 07 54
							39 00 00 03 51 07 55
							39 00 00 03 51 07 56
							39 00 00 03 51 07 57
							39 00 00 03 51 07 58
							39 00 00 03 51 07 59
							39 00 00 03 51 07 5A
							39 00 00 03 51 07 5B
							39 00 00 03 51 07 5C
							39 00 00 03 51 07 5D
							39 00 00 03 51 07 5E
							39 00 00 03 51 07 5F
							39 00 00 03 51 07 60
							39 00 00 03 51 07 61
							39 00 00 03 51 07 62
							39 00 00 03 51 07 63
							39 00 00 03 51 07 64
							39 00 00 03 51 07 65
							39 00 00 03 51 07 66
							39 00 00 03 51 07 67
							39 00 00 03 51 07 68
							39 00 00 03 51 07 69
							39 00 00 03 51 07 6A
							39 00 00 03 51 07 6B
							39 00 00 03 51 07 6C
							39 00 00 03 51 07 6D
							39 00 00 03 51 07 6E
							39 00 00 03 51 07 6F
							39 00 00 03 51 07 70
							39 00 00 03 51 07 71
							39 00 00 03 51 07 72
							39 00 00 03 51 07 73
							39 00 00 03 51 07 74
							39 00 00 03 51 07 75
							39 00 00 03 51 07 76
							39 00 00 03 51 07 77
							39 00 00 03 51 07 78
							39 00 00 03 51 07 79
							39 00 00 03 51 07 7A
							39 00 00 03 51 07 7B
							39 00 00 03 51 07 7C
							39 00 00 03 51 07 7D
							39 00 00 03 51 07 7E
							39 00 00 03 51 07 7F
							39 00 00 03 51 07 80
							39 00 00 03 51 07 81
							39 00 00 03 51 07 82
							39 00 00 03 51 07 83
							39 00 00 03 51 07 84
							39 00 00 03 51 07 85
							39 00 00 03 51 07 86
							39 00 00 03 51 07 87
							39 00 00 03 51 07 88
							39 00 00 03 51 07 89
							39 00 00 03 51 07 8A
							39 00 00 03 51 07 8B
							39 00 00 03 51 07 8C
							39 00 00 03 51 07 8D
							39 00 00 03 51 07 8E
							39 00 00 03 51 07 8F
							39 00 00 03 51 07 90
							39 00 00 03 51 07 91
							39 00 00 03 51 07 92
							39 00 00 03 51 07 93
							39 00 00 03 51 07 94
							39 00 00 03 51 07 95
							39 00 00 03 51 07 96
							39 00 00 03 51 07 97
							39 00 00 03 51 07 98
							39 00 00 03 51 07 99
							39 00 00 03 51 07 9A
							39 00 00 03 51 07 9B
							39 00 00 03 51 07 9C
							39 00 00 03 51 07 9D
							39 00 00 03 51 07 9E
							39 00 00 03 51 07 9F
							39 00 00 03 51 07 A0
							39 00 00 03 51 07 A1
							39 00 00 03 51 07 A2
							39 00 00 03 51 07 A3
							39 00 00 03 51 07 A4
							39 00 00 03 51 07 A5
							39 00 00 03 51 07 A6
							39 00 00 03 51 07 A7
							39 00 00 03 51 07 A8
							39 00 00 03 51 07 A9
							39 00 00 03 51 07 AA
							39 00 00 03 51 07 AB
							39 00 00 03 51 07 AC
							39 00 00 03 51 07 AD
							39 00 00 03 51 07 AE
							39 00 00 03 51 07 AF
							39 00 00 03 51 07 B0
							39 00 00 03 51 07 B1
							39 00 00 03 51 07 B2
							39 00 00 03 51 07 B3
							39 00 00 03 51 07 B4
							39 00 00 03 51 07 B5
							39 00 00 03 51 07 B6
							39 00 00 03 51 07 B7
							39 00 00 03 51 07 B8
							39 00 00 03 51 07 B9
							39 00 00 03 51 07 BA
							39 00 00 03 51 07 BB
							39 00 00 03 51 07 BC
							39 00 00 03 51 07 BD
							39 00 00 03 51 07 BE
							39 00 00 03 51 07 BF
							39 00 00 03 51 07 C0
							39 00 00 03 51 07 C1
							39 00 00 03 51 07 C2
							39 00 00 03 51 07 C3
							39 00 00 03 51 07 C4
							39 00 00 03 51 07 C5
							39 00 00 03 51 07 C6
							39 00 00 03 51 07 C7
							39 00 00 03 51 07 C8
							39 00 00 03 51 07 C9
							39 00 00 03 51 07 CA
							39 00 00 03 51 07 CB
							39 00 00 03 51 07 CC
							39 00 00 03 51 07 CD
							39 00 00 03 51 07 CE
							39 00 00 03 51 07 CF
							39 00 00 03 51 07 D0
							39 00 00 03 51 07 D1
							39 00 00 03 51 07 D2
							39 00 00 03 51 07 D3
							39 00 00 03 51 07 D4
							39 00 00 03 51 07 D5
							39 00 00 03 51 07 D6
							39 00 00 03 51 07 D7
							39 00 00 03 51 07 D8
							39 00 00 03 51 07 D9
							39 00 00 03 51 07 DA
							39 00 00 03 51 07 DB
							39 00 00 03 51 07 DC
							39 00 00 03 51 07 DD
							39 00 00 03 51 07 DE
							39 00 00 03 51 07 DF
							39 00 00 03 51 07 E0
							39 00 00 03 51 07 E1
							39 00 00 03 51 07 E2
							39 00 00 03 51 07 E3
							39 00 00 03 51 07 E4
							39 00 00 03 51 07 E5
							39 00 00 03 51 07 E6
							39 00 00 03 51 07 E7
							39 00 00 03 51 07 E8
							39 00 00 03 51 07 E9
							39 00 00 03 51 07 EA
							39 00 00 03 51 07 EB
							39 00 00 03 51 07 EC
							39 00 00 03 51 07 ED
							39 00 00 03 51 07 EE
							39 00 00 03 51 07 EF
							39 00 00 03 51 07 F0
							39 00 00 03 51 07 F1
							39 00 00 03 51 07 F2
							39 00 00 03 51 07 F3
							39 00 00 03 51 07 F4
							39 00 00 03 51 07 F5
							39 00 00 03 51 07 F6
							39 00 00 03 51 07 F7
							39 00 00 03 51 07 F8
							39 00 00 03 51 07 F9
							39 00 00 03 51 07 FA
							39 00 00 03 51 07 FB
							39 00 00 03 51 07 FC
							39 00 00 03 51 07 FD
							39 00 00 03 51 07 FE
							39 00 00 03 51 07 FF
							39 00 00 03 51 08 00
							39 00 00 03 51 08 01
							39 00 00 03 51 08 02
							39 00 00 03 51 08 03
							39 00 00 03 51 08 04
							39 00 00 03 51 08 05
							39 00 00 03 51 08 06
							39 00 00 03 51 08 07
							39 00 00 03 51 08 08
							39 00 00 03 51 08 09
							39 00 00 03 51 08 0A
							39 00 00 03 51 08 0B
							39 00 00 03 51 08 0C
							39 00 00 03 51 08 0D
							39 00 00 03 51 08 0E
							39 00 00 03 51 08 0F
							39 00 00 03 51 08 10
							39 00 00 03 51 08 11
							39 00 00 03 51 08 12
							39 00 00 03 51 08 13
							39 00 00 03 51 08 14
							39 00 00 03 51 08 15
							39 00 00 03 51 08 16
							39 00 00 03 51 08 17
							39 00 00 03 51 08 18
							39 00 00 03 51 08 19
							39 00 00 03 51 08 1A
							39 00 00 03 51 08 1B
							39 00 00 03 51 08 1C
							39 00 00 03 51 08 1D
							39 00 00 03 51 08 1E
							39 00 00 03 51 08 1F
							39 00 00 03 51 08 20
							39 00 00 03 51 08 21
							39 00 00 03 51 08 22
							39 00 00 03 51 08 23
							39 00 00 03 51 08 24
							39 00 00 03 51 08 25
							39 00 00 03 51 08 26
							39 00 00 03 51 08 27
							39 00 00 03 51 08 28
							39 00 00 03 51 08 29
							39 00 00 03 51 08 2A
							39 00 00 03 51 08 2B
							39 00 00 03 51 08 2C
							39 00 00 03 51 08 2D
							39 00 00 03 51 08 2E
							39 00 00 03 51 08 2F
							39 00 00 03 51 08 30
							39 00 00 03 51 08 31
							39 00 00 03 51 08 32
							39 00 00 03 51 08 33
							39 00 00 03 51 08 34
							39 00 00 03 51 08 35
							39 00 00 03 51 08 36
							39 00 00 03 51 08 37
							39 00 00 03 51 08 38
							39 00 00 03 51 08 39
							39 00 00 03 51 08 3A
							39 00 00 03 51 08 3B
							39 00 00 03 51 08 3C
							39 00 00 03 51 08 3D
							39 00 00 03 51 08 3E
							39 00 00 03 51 08 3F
							39 00 00 03 51 08 40
							39 00 00 03 51 08 41
							39 00 00 03 51 08 42
							39 00 00 03 51 08 43
							39 00 00 03 51 08 44
							39 00 00 03 51 08 45
							39 00 00 03 51 08 46
							39 00 00 03 51 08 47
							39 00 00 03 51 08 48
							39 00 00 03 51 08 49
							39 00 00 03 51 08 4A
							39 00 00 03 51 08 4B
							39 00 00 03 51 08 4C
							39 00 00 03 51 08 4D
							39 00 00 03 51 08 4E
							39 00 00 03 51 08 4F
							39 00 00 03 51 08 50
							39 00 00 03 51 08 51
							39 00 00 03 51 08 52
							39 00 00 03 51 08 53
							39 00 00 03 51 08 54
							39 00 00 03 51 08 55
							39 00 00 03 51 08 56
							39 00 00 03 51 08 57
							39 00 00 03 51 08 58
							39 00 00 03 51 08 59
							39 00 00 03 51 08 5A
							39 00 00 03 51 08 5B
							39 00 00 03 51 08 5C
							39 00 00 03 51 08 5D
							39 00 00 03 51 08 5E
							39 00 00 03 51 08 5F
							39 00 00 03 51 08 60
							39 00 00 03 51 08 61
							39 00 00 03 51 08 62
							39 00 00 03 51 08 63
							39 00 00 03 51 08 64
							39 00 00 03 51 08 65
							39 00 00 03 51 08 66
							39 00 00 03 51 08 67
							39 00 00 03 51 08 68
							39 00 00 03 51 08 69
							39 00 00 03 51 08 6A
							39 00 00 03 51 08 6B
							39 00 00 03 51 08 6C
							39 00 00 03 51 08 6D
							39 00 00 03 51 08 6E
							39 00 00 03 51 08 6F
							39 00 00 03 51 08 70
							39 00 00 03 51 08 71
							39 00 00 03 51 08 72
							39 00 00 03 51 08 73
							39 00 00 03 51 08 74
							39 00 00 03 51 08 75
							39 00 00 03 51 08 76
							39 00 00 03 51 08 77
							39 00 00 03 51 08 78
							39 00 00 03 51 08 79
							39 00 00 03 51 08 7A
							39 00 00 03 51 08 7B
							39 00 00 03 51 08 7C
							39 00 00 03 51 08 7D
							39 00 00 03 51 08 7E
							39 00 00 03 51 08 7F
							39 00 00 03 51 08 80
							39 00 00 03 51 08 81
							39 00 00 03 51 08 82
							39 00 00 03 51 08 83
							39 00 00 03 51 08 84
							39 00 00 03 51 08 85
							39 00 00 03 51 08 86
							39 00 00 03 51 08 87
							39 00 00 03 51 08 88
							39 00 00 03 51 08 89
							39 00 00 03 51 08 8A
							39 00 00 03 51 08 8B
							39 00 00 03 51 08 8C
							39 00 00 03 51 08 8D
							39 00 00 03 51 08 8E
							39 00 00 03 51 08 8F
							39 00 00 03 51 08 90
							39 00 00 03 51 08 91
							39 00 00 03 51 08 92
							39 00 00 03 51 08 93
							39 00 00 03 51 08 94
							39 00 00 03 51 08 95
							39 00 00 03 51 08 96
							39 00 00 03 51 08 97
							39 00 00 03 51 08 98
							39 00 00 03 51 08 99
							39 00 00 03 51 08 9A
							39 00 00 03 51 08 9B
							39 00 00 03 51 08 9C
							39 00 00 03 51 08 9D
							39 00 00 03 51 08 9E
							39 00 00 03 51 08 9F
							39 00 00 03 51 08 A0
							39 00 00 03 51 08 A1
							39 00 00 03 51 08 A2
							39 00 00 03 51 08 A3
							39 00 00 03 51 08 A4
							39 00 00 03 51 08 A5
							39 00 00 03 51 08 A6
							39 00 00 03 51 08 A7
							39 00 00 03 51 08 A8
							39 00 00 03 51 08 A9
							39 00 00 03 51 08 AA
							39 00 00 03 51 08 AB
							39 00 00 03 51 08 AC
							39 00 00 03 51 08 AD
							39 00 00 03 51 08 AE
							39 00 00 03 51 08 AF
							39 00 00 03 51 08 B0
							39 00 00 03 51 08 B1
							39 00 00 03 51 08 B2
							39 00 00 03 51 08 B3
							39 00 00 03 51 08 B4
							39 00 00 03 51 08 B5
							39 00 00 03 51 08 B6
							39 00 00 03 51 08 B7
							39 00 00 03 51 08 B8
							39 00 00 03 51 08 B9
							39 00 00 03 51 08 BA
							39 00 00 03 51 08 BB
							39 00 00 03 51 08 BC
							39 00 00 03 51 08 BD
							39 00 00 03 51 08 BE
							39 00 00 03 51 08 BF
							39 00 00 03 51 08 C0
							39 00 00 03 51 08 C1
							39 00 00 03 51 08 C2
							39 00 00 03 51 08 C3
							39 00 00 03 51 08 C4
							39 00 00 03 51 08 C5
							39 00 00 03 51 08 C6
							39 00 00 03 51 08 C7
							39 00 00 03 51 08 C8
							39 00 00 03 51 08 C9
							39 00 00 03 51 08 CA
							39 00 00 03 51 08 CB
							39 00 00 03 51 08 CC
							39 00 00 03 51 08 CD
							39 00 00 03 51 08 CE
							39 00 00 03 51 08 CF
							39 00 00 03 51 08 D0
							39 00 00 03 51 08 D1
							39 00 00 03 51 08 D2
							39 00 00 03 51 08 D3
							39 00 00 03 51 08 D4
							39 00 00 03 51 08 D5
							39 00 00 03 51 08 D6
							39 00 00 03 51 08 D7
							39 00 00 03 51 08 D8
							39 00 00 03 51 08 D9
							39 00 00 03 51 08 DA
							39 00 00 03 51 08 DB
							39 00 00 03 51 08 DC
							39 00 00 03 51 08 DD
							39 00 00 03 51 08 DE
							39 00 00 03 51 08 DF
							39 00 00 03 51 08 E0
							39 00 00 03 51 08 E1
							39 00 00 03 51 08 E2
							39 00 00 03 51 08 E3
							39 00 00 03 51 08 E4
							39 00 00 03 51 08 E5
							39 00 00 03 51 08 E6
							39 00 00 03 51 08 E7
							39 00 00 03 51 08 E8
							39 00 00 03 51 08 E9
							39 00 00 03 51 08 EA
							39 00 00 03 51 08 EB
							39 00 00 03 51 08 EC
							39 00 00 03 51 08 ED
							39 00 00 03 51 08 EE
							39 00 00 03 51 08 EF
							39 00 00 03 51 08 F0
							39 00 00 03 51 08 F1
							39 00 00 03 51 08 F2
							39 00 00 03 51 08 F3
							39 00 00 03 51 08 F4
							39 00 00 03 51 08 F5
							39 00 00 03 51 08 F6
							39 00 00 03 51 08 F7
							39 00 00 03 51 08 F8
							39 00 00 03 51 08 F9
							39 00 00 03 51 08 FA
							39 00 00 03 51 08 FB
							39 00 00 03 51 08 FC
							39 00 00 03 51 08 FD
							39 00 00 03 51 08 FE
							39 00 00 03 51 08 FF
							39 00 00 03 51 09 00
							39 00 00 03 51 09 01
							39 00 00 03 51 09 02
							39 00 00 03 51 09 03
							39 00 00 03 51 09 04
							39 00 00 03 51 09 05
							39 00 00 03 51 09 06
							39 00 00 03 51 09 07
							39 00 00 03 51 09 08
							39 00 00 03 51 09 09
							39 00 00 03 51 09 0A
							39 00 00 03 51 09 0B
							39 00 00 03 51 09 0C
							39 00 00 03 51 09 0D
							39 00 00 03 51 09 0E
							39 00 00 03 51 09 0F
							39 00 00 03 51 09 10
							39 00 00 03 51 09 11
							39 00 00 03 51 09 12
							39 00 00 03 51 09 13
							39 00 00 03 51 09 14
							39 00 00 03 51 09 15
							39 00 00 03 51 09 16
							39 00 00 03 51 09 17
							39 00 00 03 51 09 18
							39 00 00 03 51 09 19
							39 00 00 03 51 09 1A
							39 00 00 03 51 09 1B
							39 00 00 03 51 09 1C
							39 00 00 03 51 09 1D
							39 00 00 03 51 09 1E
							39 00 00 03 51 09 1F
							39 00 00 03 51 09 20
							39 00 00 03 51 09 21
							39 00 00 03 51 09 22
							39 00 00 03 51 09 23
							39 00 00 03 51 09 24
							39 00 00 03 51 09 25
							39 00 00 03 51 09 26
							39 00 00 03 51 09 27
							39 00 00 03 51 09 28
							39 00 00 03 51 09 29
							39 00 00 03 51 09 2A
							39 00 00 03 51 09 2B
							39 00 00 03 51 09 2C
							39 00 00 03 51 09 2D
							39 00 00 03 51 09 2E
							39 00 00 03 51 09 2F
							39 00 00 03 51 09 30
							39 00 00 03 51 09 31
							39 00 00 03 51 09 32
							39 00 00 03 51 09 33
							39 00 00 03 51 09 34
							39 00 00 03 51 09 35
							39 00 00 03 51 09 36
							39 00 00 03 51 09 37
							39 00 00 03 51 09 38
							39 00 00 03 51 09 39
							39 00 00 03 51 09 3A
							39 00 00 03 51 09 3B
							39 00 00 03 51 09 3C
							39 00 00 03 51 09 3D
							39 00 00 03 51 09 3E
							39 00 00 03 51 09 3F
							39 00 00 03 51 09 40
							39 00 00 03 51 09 41
							39 00 00 03 51 09 42
							39 00 00 03 51 09 43
							39 00 00 03 51 09 44
							39 00 00 03 51 09 45
							39 00 00 03 51 09 46
							39 00 00 03 51 09 47
							39 00 00 03 51 09 48
							39 00 00 03 51 09 49
							39 00 00 03 51 09 4A
							39 00 00 03 51 09 4B
							39 00 00 03 51 09 4C
							39 00 00 03 51 09 4D
							39 00 00 03 51 09 4E
							39 00 00 03 51 09 4F
							39 00 00 03 51 09 50
							39 00 00 03 51 09 51
							39 00 00 03 51 09 52
							39 00 00 03 51 09 53
							39 00 00 03 51 09 54
							39 00 00 03 51 09 55
							39 00 00 03 51 09 56
							39 00 00 03 51 09 57
							39 00 00 03 51 09 58
							39 00 00 03 51 09 59
							39 00 00 03 51 09 5A
							39 00 00 03 51 09 5B
							39 00 00 03 51 09 5C
							39 00 00 03 51 09 5D
							39 00 00 03 51 09 5E
							39 00 00 03 51 09 5F
							39 00 00 03 51 09 60
							39 00 00 03 51 09 61
							39 00 00 03 51 09 62
							39 00 00 03 51 09 63
							39 00 00 03 51 09 64
							39 00 00 03 51 09 65
							39 00 00 03 51 09 66
							39 00 00 03 51 09 67
							39 00 00 03 51 09 68
							39 00 00 03 51 09 69
							39 00 00 03 51 09 6A
							39 00 00 03 51 09 6B
							39 00 00 03 51 09 6C
							39 00 00 03 51 09 6D
							39 00 00 03 51 09 6E
							39 00 00 03 51 09 6F
							39 00 00 03 51 09 70
							39 00 00 03 51 09 71
							39 00 00 03 51 09 72
							39 00 00 03 51 09 73
							39 00 00 03 51 09 74
							39 00 00 03 51 09 75
							39 00 00 03 51 09 76
							39 00 00 03 51 09 77
							39 00 00 03 51 09 78
							39 00 00 03 51 09 79
							39 00 00 03 51 09 7A
							39 00 00 03 51 09 7B
							39 00 00 03 51 09 7C
							39 00 00 03 51 09 7D
							39 00 00 03 51 09 7E
							39 00 00 03 51 09 7F
							39 00 00 03 51 09 80
							39 00 00 03 51 09 81
							39 00 00 03 51 09 82
							39 00 00 03 51 09 83
							39 00 00 03 51 09 84
							39 00 00 03 51 09 85
							39 00 00 03 51 09 86
							39 00 00 03 51 09 87
							39 00 00 03 51 09 88
							39 00 00 03 51 09 89
							39 00 00 03 51 09 8A
							39 00 00 03 51 09 8B
							39 00 00 03 51 09 8C
							39 00 00 03 51 09 8D
							39 00 00 03 51 09 8E
							39 00 00 03 51 09 8F
							39 00 00 03 51 09 90
							39 00 00 03 51 09 91
							39 00 00 03 51 09 92
							39 00 00 03 51 09 93
							39 00 00 03 51 09 94
							39 00 00 03 51 09 95
							39 00 00 03 51 09 96
							39 00 00 03 51 09 97
							39 00 00 03 51 09 98
							39 00 00 03 51 09 99
							39 00 00 03 51 09 9A
							39 00 00 03 51 09 9B
							39 00 00 03 51 09 9C
							39 00 00 03 51 09 9D
							39 00 00 03 51 09 9E
							39 00 00 03 51 09 9F
							39 00 00 03 51 09 A0
							39 00 00 03 51 09 A1
							39 00 00 03 51 09 A2
							39 00 00 03 51 09 A3
							39 00 00 03 51 09 A4
							39 00 00 03 51 09 A5
							39 00 00 03 51 09 A6
							39 00 00 03 51 09 A7
							39 00 00 03 51 09 A8
							39 00 00 03 51 09 A9
							39 00 00 03 51 09 AA
							39 00 00 03 51 09 AB
							39 00 00 03 51 09 AC
							39 00 00 03 51 09 AD
							39 00 00 03 51 09 AE
							39 00 00 03 51 09 AF
							39 00 00 03 51 09 B0
							39 00 00 03 51 09 B1
							39 00 00 03 51 09 B2
							39 00 00 03 51 09 B3
							39 00 00 03 51 09 B4
							39 00 00 03 51 09 B5
							39 00 00 03 51 09 B6
							39 00 00 03 51 09 B7
							39 00 00 03 51 09 B8
							39 00 00 03 51 09 B9
							39 00 00 03 51 09 BA
							39 00 00 03 51 09 BB
							39 00 00 03 51 09 BC
							39 00 00 03 51 09 BD
							39 00 00 03 51 09 BE
							39 00 00 03 51 09 BF
							39 00 00 03 51 09 C0
							39 00 00 03 51 09 C1
							39 00 00 03 51 09 C2
							39 00 00 03 51 09 C3
							39 00 00 03 51 09 C4
							39 00 00 03 51 09 C5
							39 00 00 03 51 09 C6
							39 00 00 03 51 09 C7
							39 00 00 03 51 09 C8
							39 00 00 03 51 09 C9
							39 00 00 03 51 09 CA
							39 00 00 03 51 09 CB
							39 00 00 03 51 09 CC
							39 00 00 03 51 09 CD
							39 00 00 03 51 09 CE
							39 00 00 03 51 09 CF
							39 00 00 03 51 09 D0
							39 00 00 03 51 09 D1
							39 00 00 03 51 09 D2
							39 00 00 03 51 09 D3
							39 00 00 03 51 09 D4
							39 00 00 03 51 09 D5
							39 00 00 03 51 09 D6
							39 00 00 03 51 09 D7
							39 00 00 03 51 09 D8
							39 00 00 03 51 09 D9
							39 00 00 03 51 09 DA
							39 00 00 03 51 09 DB
							39 00 00 03 51 09 DC
							39 00 00 03 51 09 DD
							39 00 00 03 51 09 DE
							39 00 00 03 51 09 DF
							39 00 00 03 51 09 E0
							39 00 00 03 51 09 E1
							39 00 00 03 51 09 E2
							39 00 00 03 51 09 E3
							39 00 00 03 51 09 E4
							39 00 00 03 51 09 E5
							39 00 00 03 51 09 E6
							39 00 00 03 51 09 E7
							39 00 00 03 51 09 E8
							39 00 00 03 51 09 E9
							39 00 00 03 51 09 EA
							39 00 00 03 51 09 EB
							39 00 00 03 51 09 EC
							39 00 00 03 51 09 ED
							39 00 00 03 51 09 EE
							39 00 00 03 51 09 EF
							39 00 00 03 51 09 F0
							39 00 00 03 51 09 F1
							39 00 00 03 51 09 F2
							39 00 00 03 51 09 F3
							39 00 00 03 51 09 F4
							39 00 00 03 51 09 F5
							39 00 00 03 51 09 F6
							39 00 00 03 51 09 F7
							39 00 00 03 51 09 F8
							39 00 00 03 51 09 F9
							39 00 00 03 51 09 FA
							39 00 00 03 51 09 FB
							39 00 00 03 51 09 FC
							39 00 00 03 51 09 FD
							39 00 00 03 51 09 FE
							39 00 00 03 51 09 FF
							39 00 00 03 51 0A 00
							39 00 00 03 51 0A 01
							39 00 00 03 51 0A 02
							39 00 00 03 51 0A 03
							39 00 00 03 51 0A 04
							39 00 00 03 51 0A 05
							39 00 00 03 51 0A 06
							39 00 00 03 51 0A 07
							39 00 00 03 51 0A 08
							39 00 00 03 51 0A 09
							39 00 00 03 51 0A 0A
							39 00 00 03 51 0A 0B
							39 00 00 03 51 0A 0C
							39 00 00 03 51 0A 0D
							39 00 00 03 51 0A 0E
							39 00 00 03 51 0A 0F
							39 00 00 03 51 0A 10
							39 00 00 03 51 0A 11
							39 00 00 03 51 0A 12
							39 00 00 03 51 0A 13
							39 00 00 03 51 0A 14
							39 00 00 03 51 0A 15
							39 00 00 03 51 0A 16
							39 00 00 03 51 0A 17
							39 00 00 03 51 0A 18
							39 00 00 03 51 0A 19
							39 00 00 03 51 0A 1A
							39 00 00 03 51 0A 1B
							39 00 00 03 51 0A 1C
							39 00 00 03 51 0A 1D
							39 00 00 03 51 0A 1E
							39 00 00 03 51 0A 1F
							39 00 00 03 51 0A 20
							39 00 00 03 51 0A 21
							39 00 00 03 51 0A 22
							39 00 00 03 51 0A 23
							39 00 00 03 51 0A 24
							39 00 00 03 51 0A 25
							39 00 00 03 51 0A 26
							39 00 00 03 51 0A 27
							39 00 00 03 51 0A 28
							39 00 00 03 51 0A 29
							39 00 00 03 51 0A 2A
							39 00 00 03 51 0A 2B
							39 00 00 03 51 0A 2C
							39 00 00 03 51 0A 2D
							39 00 00 03 51 0A 2E
							39 00 00 03 51 0A 2F
							39 00 00 03 51 0A 30
							39 00 00 03 51 0A 31
							39 00 00 03 51 0A 32
							39 00 00 03 51 0A 33
							39 00 00 03 51 0A 34
							39 00 00 03 51 0A 35
							39 00 00 03 51 0A 36
							39 00 00 03 51 0A 37
							39 00 00 03 51 0A 38
							39 00 00 03 51 0A 39
							39 00 00 03 51 0A 3A
							39 00 00 03 51 0A 3B
							39 00 00 03 51 0A 3C
							39 00 00 03 51 0A 3D
							39 00 00 03 51 0A 3E
							39 00 00 03 51 0A 3F
							39 00 00 03 51 0A 40
							39 00 00 03 51 0A 41
							39 00 00 03 51 0A 42
							39 00 00 03 51 0A 43
							39 00 00 03 51 0A 44
							39 00 00 03 51 0A 45
							39 00 00 03 51 0A 46
							39 00 00 03 51 0A 47
							39 00 00 03 51 0A 48
							39 00 00 03 51 0A 49
							39 00 00 03 51 0A 4A
							39 00 00 03 51 0A 4B
							39 00 00 03 51 0A 4C
							39 00 00 03 51 0A 4D
							39 00 00 03 51 0A 4E
							39 00 00 03 51 0A 4F
							39 00 00 03 51 0A 50
							39 00 00 03 51 0A 51
							39 00 00 03 51 0A 52
							39 00 00 03 51 0A 53
							39 00 00 03 51 0A 54
							39 00 00 03 51 0A 55
							39 00 00 03 51 0A 56
							39 00 00 03 51 0A 57
							39 00 00 03 51 0A 58
							39 00 00 03 51 0A 59
							39 00 00 03 51 0A 5A
							39 00 00 03 51 0A 5B
							39 00 00 03 51 0A 5C
							39 00 00 03 51 0A 5D
							39 00 00 03 51 0A 5E
							39 00 00 03 51 0A 5F
							39 00 00 03 51 0A 60
							39 00 00 03 51 0A 61
							39 00 00 03 51 0A 62
							39 00 00 03 51 0A 63
							39 00 00 03 51 0A 64
							39 00 00 03 51 0A 65
							39 00 00 03 51 0A 66
							39 00 00 03 51 0A 67
							39 00 00 03 51 0A 68
							39 00 00 03 51 0A 69
							39 00 00 03 51 0A 6A
							39 00 00 03 51 0A 6B
							39 00 00 03 51 0A 6C
							39 00 00 03 51 0A 6D
							39 00 00 03 51 0A 6E
							39 00 00 03 51 0A 6F
							39 00 00 03 51 0A 70
							39 00 00 03 51 0A 71
							39 00 00 03 51 0A 72
							39 00 00 03 51 0A 73
							39 00 00 03 51 0A 74
							39 00 00 03 51 0A 75
							39 00 00 03 51 0A 76
							39 00 00 03 51 0A 77
							39 00 00 03 51 0A 78
							39 00 00 03 51 0A 79
							39 00 00 03 51 0A 7A
							39 00 00 03 51 0A 7B
							39 00 00 03 51 0A 7C
							39 00 00 03 51 0A 7D
							39 00 00 03 51 0A 7E
							39 00 00 03 51 0A 7F
							39 00 00 03 51 0A 80
							39 00 00 03 51 0A 81
							39 00 00 03 51 0A 82
							39 00 00 03 51 0A 83
							39 00 00 03 51 0A 84
							39 00 00 03 51 0A 85
							39 00 00 03 51 0A 86
							39 00 00 03 51 0A 87
							39 00 00 03 51 0A 88
							39 00 00 03 51 0A 89
							39 00 00 03 51 0A 8A
							39 00 00 03 51 0A 8B
							39 00 00 03 51 0A 8C
							39 00 00 03 51 0A 8D
							39 00 00 03 51 0A 8E
							39 00 00 03 51 0A 8F
							39 00 00 03 51 0A 90
							39 00 00 03 51 0A 91
							39 00 00 03 51 0A 92
							39 00 00 03 51 0A 93
							39 00 00 03 51 0A 94
							39 00 00 03 51 0A 95
							39 00 00 03 51 0A 96
							39 00 00 03 51 0A 97
							39 00 00 03 51 0A 98
							39 00 00 03 51 0A 99
							39 00 00 03 51 0A 9A
							39 00 00 03 51 0A 9B
							39 00 00 03 51 0A 9C
							39 00 00 03 51 0A 9D
							39 00 00 03 51 0A 9E
							39 00 00 03 51 0A 9F
							39 00 00 03 51 0A A0
							39 00 00 03 51 0A A1
							39 00 00 03 51 0A A2
							39 00 00 03 51 0A A3
							39 00 00 03 51 0A A4
							39 00 00 03 51 0A A5
							39 00 00 03 51 0A A6
							39 00 00 03 51 0A A7
							39 00 00 03 51 0A A8
							39 00 00 03 51 0A A9
							39 00 00 03 51 0A AA
							39 00 00 03 51 0A AB
							39 00 00 03 51 0A AC
							39 00 00 03 51 0A AD
							39 00 00 03 51 0A AE
							39 00 00 03 51 0A AF
							39 00 00 03 51 0A B0
							39 00 00 03 51 0A B1
							39 00 00 03 51 0A B2
							39 00 00 03 51 0A B3
							39 00 00 03 51 0A B4
							39 00 00 03 51 0A B5
							39 00 00 03 51 0A B6
							39 00 00 03 51 0A B7
							39 00 00 03 51 0A B8
							39 00 00 03 51 0A B9
							39 00 00 03 51 0A BA
							39 00 00 03 51 0A BB
							39 00 00 03 51 0A BC
							39 00 00 03 51 0A BD
							39 00 00 03 51 0A BE
							39 00 00 03 51 0A BF
							39 00 00 03 51 0A C0
							39 00 00 03 51 0A C1
							39 00 00 03 51 0A C2
							39 00 00 03 51 0A C3
							39 00 00 03 51 0A C4
							39 00 00 03 51 0A C5
							39 00 00 03 51 0A C6
							39 00 00 03 51 0A C7
							39 00 00 03 51 0A C8
							39 00 00 03 51 0A C9
							39 00 00 03 51 0A CA
							39 00 00 03 51 0A CB
							39 00 00 03 51 0A CC
							39 00 00 03 51 0A CD
							39 00 00 03 51 0A CE
							39 00 00 03 51 0A CF
							39 00 00 03 51 0A D0
							39 00 00 03 51 0A D1
							39 00 00 03 51 0A D2
							39 00 00 03 51 0A D3
							39 00 00 03 51 0A D4
							39 00 00 03 51 0A D5
							39 00 00 03 51 0A D6
							39 00 00 03 51 0A D7
							39 00 00 03 51 0A D8
							39 00 00 03 51 0A D9
							39 00 00 03 51 0A DA
							39 00 00 03 51 0A DB
							39 00 00 03 51 0A DC
							39 00 00 03 51 0A DD
							39 00 00 03 51 0A DE
							39 00 00 03 51 0A DF
							39 00 00 03 51 0A E0
							39 00 00 03 51 0A E1
							39 00 00 03 51 0A E2
							39 00 00 03 51 0A E3
							39 00 00 03 51 0A E4
							39 00 00 03 51 0A E5
							39 00 00 03 51 0A E6
							39 00 00 03 51 0A E7
							39 00 00 03 51 0A E8
							39 00 00 03 51 0A E9
							39 00 00 03 51 0A EA
							39 00 00 03 51 0A EB
							39 00 00 03 51 0A EC
							39 00 00 03 51 0A ED
							39 00 00 03 51 0A EE
							39 00 00 03 51 0A EF
							39 00 00 03 51 0A F0
							39 00 00 03 51 0A F1
							39 00 00 03 51 0A F2
							39 00 00 03 51 0A F3
							39 00 00 03 51 0A F4
							39 00 00 03 51 0A F5
							39 00 00 03 51 0A F6
							39 00 00 03 51 0A F7
							39 00 00 03 51 0A F8
							39 00 00 03 51 0A F9
							39 00 00 03 51 0A FA
							39 00 00 03 51 0A FB
							39 00 00 03 51 0A FC
							39 00 00 03 51 0A FD
							39 00 00 03 51 0A FE
							39 00 00 03 51 0A FF
							39 00 00 03 51 0B 00
							39 00 00 03 51 0B 01
							39 00 00 03 51 0B 02
							39 00 00 03 51 0B 03
							39 00 00 03 51 0B 04
							39 00 00 03 51 0B 05
							39 00 00 03 51 0B 06
							39 00 00 03 51 0B 07
							39 00 00 03 51 0B 08
							39 00 00 03 51 0B 09
							39 00 00 03 51 0B 0A
							39 00 00 03 51 0B 0B
							39 00 00 03 51 0B 0C
							39 00 00 03 51 0B 0D
							39 00 00 03 51 0B 0E
							39 00 00 03 51 0B 0F
							39 00 00 03 51 0B 10
							39 00 00 03 51 0B 11
							39 00 00 03 51 0B 12
							39 00 00 03 51 0B 13
							39 00 00 03 51 0B 14
							39 00 00 03 51 0B 15
							39 00 00 03 51 0B 16
							39 00 00 03 51 0B 17
							39 00 00 03 51 0B 18
							39 00 00 03 51 0B 19
							39 00 00 03 51 0B 1A
							39 00 00 03 51 0B 1B
							39 00 00 03 51 0B 1C
							39 00 00 03 51 0B 1D
							39 00 00 03 51 0B 1E
							39 00 00 03 51 0B 1F
							39 00 00 03 51 0B 20
							39 00 00 03 51 0B 21
							39 00 00 03 51 0B 22
							39 00 00 03 51 0B 23
							39 00 00 03 51 0B 24
							39 00 00 03 51 0B 25
							39 00 00 03 51 0B 26
							39 00 00 03 51 0B 27
							39 00 00 03 51 0B 28
							39 00 00 03 51 0B 29
							39 00 00 03 51 0B 2A
							39 00 00 03 51 0B 2B
							39 00 00 03 51 0B 2C
							39 00 00 03 51 0B 2D
							39 00 00 03 51 0B 2E
							39 00 00 03 51 0B 2F
							39 00 00 03 51 0B 30
							39 00 00 03 51 0B 31
							39 00 00 03 51 0B 32
							39 00 00 03 51 0B 33
							39 00 00 03 51 0B 34
							39 00 00 03 51 0B 35
							39 00 00 03 51 0B 36
							39 00 00 03 51 0B 37
							39 00 00 03 51 0B 38
							39 00 00 03 51 0B 39
							39 00 00 03 51 0B 3A
							39 00 00 03 51 0B 3B
							39 00 00 03 51 0B 3C
							39 00 00 03 51 0B 3D
							39 00 00 03 51 0B 3E
							39 00 00 03 51 0B 3F
							39 00 00 03 51 0B 40
							39 00 00 03 51 0B 41
							39 00 00 03 51 0B 42
							39 00 00 03 51 0B 43
							39 00 00 03 51 0B 44
							39 00 00 03 51 0B 45
							39 00 00 03 51 0B 46
							39 00 00 03 51 0B 47
							39 00 00 03 51 0B 48
							39 00 00 03 51 0B 49
							39 00 00 03 51 0B 4A
							39 00 00 03 51 0B 4B
							39 00 00 03 51 0B 4C
							39 00 00 03 51 0B 4D
							39 00 00 03 51 0B 4E
							39 00 00 03 51 0B 4F
							39 00 00 03 51 0B 50
							39 00 00 03 51 0B 51
							39 00 00 03 51 0B 52
							39 00 00 03 51 0B 53
							39 00 00 03 51 0B 54
							39 00 00 03 51 0B 55
							39 00 00 03 51 0B 56
							39 00 00 03 51 0B 57
							39 00 00 03 51 0B 58
							39 00 00 03 51 0B 59
							39 00 00 03 51 0B 5A
							39 00 00 03 51 0B 5B
							39 00 00 03 51 0B 5C
							39 00 00 03 51 0B 5D
							39 00 00 03 51 0B 5E
							39 00 00 03 51 0B 5F
							39 00 00 03 51 0B 60
							39 00 00 03 51 0B 61
							39 00 00 03 51 0B 62
							39 00 00 03 51 0B 63
							39 00 00 03 51 0B 64
							39 00 00 03 51 0B 65
							39 00 00 03 51 0B 66
							39 00 00 03 51 0B 67
							39 00 00 03 51 0B 68
							39 00 00 03 51 0B 69
							39 00 00 03 51 0B 6A
							39 00 00 03 51 0B 6B
							39 00 00 03 51 0B 6C
							39 00 00 03 51 0B 6D
							39 00 00 03 51 0B 6E
							39 00 00 03 51 0B 6F
							39 00 00 03 51 0B 70
							39 00 00 03 51 0B 71
							39 00 00 03 51 0B 72
							39 00 00 03 51 0B 73
							39 00 00 03 51 0B 74
							39 00 00 03 51 0B 75
							39 00 00 03 51 0B 76
							39 00 00 03 51 0B 77
							39 00 00 03 51 0B 78
							39 00 00 03 51 0B 79
							39 00 00 03 51 0B 7A
							39 00 00 03 51 0B 7B
							39 00 00 03 51 0B 7C
							39 00 00 03 51 0B 7D
							39 00 00 03 51 0B 7E
							39 00 00 03 51 0B 7F
							39 00 00 03 51 0B 80
							39 00 00 03 51 0B 81
							39 00 00 03 51 0B 82
							39 00 00 03 51 0B 83
							39 00 00 03 51 0B 84
							39 00 00 03 51 0B 85
							39 00 00 03 51 0B 86
							39 00 00 03 51 0B 87
							39 00 00 03 51 0B 88
							39 00 00 03 51 0B 89
							39 00 00 03 51 0B 8A
							39 00 00 03 51 0B 8B
							39 00 00 03 51 0B 8C
							39 00 00 03 51 0B 8D
							39 00 00 03 51 0B 8E
							39 00 00 03 51 0B 8F
							39 00 00 03 51 0B 90
							39 00 00 03 51 0B 91
							39 00 00 03 51 0B 92
							39 00 00 03 51 0B 93
							39 00 00 03 51 0B 94
							39 00 00 03 51 0B 95
							39 00 00 03 51 0B 96
							39 00 00 03 51 0B 97
							39 00 00 03 51 0B 98
							39 00 00 03 51 0B 99
							39 00 00 03 51 0B 9A
							39 00 00 03 51 0B 9B
							39 00 00 03 51 0B 9C
							39 00 00 03 51 0B 9D
							39 00 00 03 51 0B 9E
							39 00 00 03 51 0B 9F
							39 00 00 03 51 0B A0
							39 00 00 03 51 0B A1
							39 00 00 03 51 0B A2
							39 00 00 03 51 0B A3
							39 00 00 03 51 0B A4
							39 00 00 03 51 0B A5
							39 00 00 03 51 0B A6
							39 00 00 03 51 0B A7
							39 00 00 03 51 0B A8
							39 00 00 03 51 0B A9
							39 00 00 03 51 0B AA
							39 00 00 03 51 0B AB
							39 00 00 03 51 0B AC
							39 00 00 03 51 0B AD
							39 00 00 03 51 0B AE
							39 00 00 03 51 0B AF
							39 00 00 03 51 0B B0
							39 00 00 03 51 0B B1
							39 00 00 03 51 0B B2
							39 00 00 03 51 0B B3
							39 00 00 03 51 0B B4
							39 00 00 03 51 0B B5
							39 00 00 03 51 0B B6
							39 00 00 03 51 0B B7
							39 00 00 03 51 0B B8
							39 00 00 03 51 0B B9
							39 00 00 03 51 0B BA
							39 00 00 03 51 0B BB
							39 00 00 03 51 0B BC
							39 00 00 03 51 0B BD
							39 00 00 03 51 0B BE
							39 00 00 03 51 0B BF
							39 00 00 03 51 0B C0
							39 00 00 03 51 0B C1
							39 00 00 03 51 0B C2
							39 00 00 03 51 0B C3
							39 00 00 03 51 0B C4
							39 00 00 03 51 0B C5
							39 00 00 03 51 0B C6
							39 00 00 03 51 0B C7
							39 00 00 03 51 0B C8
							39 00 00 03 51 0B C9
							39 00 00 03 51 0B CA
							39 00 00 03 51 0B CB
							39 00 00 03 51 0B CC
							39 00 00 03 51 0B CD
							39 00 00 03 51 0B CE
							39 00 00 03 51 0B CF
							39 00 00 03 51 0B D0
							39 00 00 03 51 0B D1
							39 00 00 03 51 0B D2
							39 00 00 03 51 0B D3
							39 00 00 03 51 0B D4
							39 00 00 03 51 0B D5
							39 00 00 03 51 0B D6
							39 00 00 03 51 0B D7
							39 00 00 03 51 0B D8
							39 00 00 03 51 0B D9
							39 00 00 03 51 0B DA
							39 00 00 03 51 0B DB
							39 00 00 03 51 0B DC
							39 00 00 03 51 0B DD
							39 00 00 03 51 0B DE
							39 00 00 03 51 0B DF
							39 00 00 03 51 0B E0
							39 00 00 03 51 0B E1
							39 00 00 03 51 0B E2
							39 00 00 03 51 0B E3
							39 00 00 03 51 0B E4
							39 00 00 03 51 0B E5
							39 00 00 03 51 0B E6
							39 00 00 03 51 0B E7
							39 00 00 03 51 0B E8
							39 00 00 03 51 0B E9
							39 00 00 03 51 0B EA
							39 00 00 03 51 0B EB
							39 00 00 03 51 0B EC
							39 00 00 03 51 0B ED
							39 00 00 03 51 0B EE
							39 00 00 03 51 0B EF
							39 00 00 03 51 0B F0
							39 00 00 03 51 0B F1
							39 00 00 03 51 0B F2
							39 00 00 03 51 0B F3
							39 00 00 03 51 0B F4
							39 00 00 03 51 0B F5
							39 00 00 03 51 0B F6
							39 00 00 03 51 0B F7
							39 00 00 03 51 0B F8
							39 00 00 03 51 0B F9
							39 00 00 03 51 0B FA
							39 00 00 03 51 0B FB
							39 00 00 03 51 0B FC
							39 00 00 03 51 0B FD
							39 00 00 03 51 0B FE
							39 00 00 03 51 0B FF
							39 00 00 03 51 0C 00
							39 00 00 03 51 0C 01
							39 00 00 03 51 0C 02
							39 00 00 03 51 0C 03
							39 00 00 03 51 0C 04
							39 00 00 03 51 0C 05
							39 00 00 03 51 0C 06
							39 00 00 03 51 0C 07
							39 00 00 03 51 0C 08
							39 00 00 03 51 0C 09
							39 00 00 03 51 0C 0A
							39 00 00 03 51 0C 0B
							39 00 00 03 51 0C 0C
							39 00 00 03 51 0C 0D
							39 00 00 03 51 0C 0E
							39 00 00 03 51 0C 0F
							39 00 00 03 51 0C 10
							39 00 00 03 51 0C 11
							39 00 00 03 51 0C 12
							39 00 00 03 51 0C 13
							39 00 00 03 51 0C 14
							39 00 00 03 51 0C 15
							39 00 00 03 51 0C 16
							39 00 00 03 51 0C 17
							39 00 00 03 51 0C 18
							39 00 00 03 51 0C 19
							39 00 00 03 51 0C 1A
							39 00 00 03 51 0C 1B
							39 00 00 03 51 0C 1C
							39 00 00 03 51 0C 1D
							39 00 00 03 51 0C 1E
							39 00 00 03 51 0C 1F
							39 00 00 03 51 0C 20
							39 00 00 03 51 0C 21
							39 00 00 03 51 0C 22
							39 00 00 03 51 0C 23
							39 00 00 03 51 0C 24
							39 00 00 03 51 0C 25
							39 00 00 03 51 0C 26
							39 00 00 03 51 0C 27
							39 00 00 03 51 0C 28
							39 00 00 03 51 0C 29
							39 00 00 03 51 0C 2A
							39 00 00 03 51 0C 2B
							39 00 00 03 51 0C 2C
							39 00 00 03 51 0C 2D
							39 00 00 03 51 0C 2E
							39 00 00 03 51 0C 2F
							39 00 00 03 51 0C 30
							39 00 00 03 51 0C 31
							39 00 00 03 51 0C 32
							39 00 00 03 51 0C 33
							39 00 00 03 51 0C 34
							39 00 00 03 51 0C 35
							39 00 00 03 51 0C 36
							39 00 00 03 51 0C 37
							39 00 00 03 51 0C 38
							39 00 00 03 51 0C 39
							39 00 00 03 51 0C 3A
							39 00 00 03 51 0C 3B
							39 00 00 03 51 0C 3C
							39 00 00 03 51 0C 3D
							39 00 00 03 51 0C 3E
							39 00 00 03 51 0C 3F
							39 00 00 03 51 0C 40
							39 00 00 03 51 0C 41
							39 00 00 03 51 0C 42
							39 00 00 03 51 0C 43
							39 00 00 03 51 0C 44
							39 00 00 03 51 0C 45
							39 00 00 03 51 0C 46
							39 00 00 03 51 0C 47
							39 00 00 03 51 0C 48
							39 00 00 03 51 0C 49
							39 00 00 03 51 0C 4A
							39 00 00 03 51 0C 4B
							39 00 00 03 51 0C 4C
							39 00 00 03 51 0C 4D
							39 00 00 03 51 0C 4E
							39 00 00 03 51 0C 4F
							39 00 00 03 51 0C 50
							39 00 00 03 51 0C 51
							39 00 00 03 51 0C 52
							39 00 00 03 51 0C 53
							39 00 00 03 51 0C 54
							39 00 00 03 51 0C 55
							39 00 00 03 51 0C 56
							39 00 00 03 51 0C 57
							39 00 00 03 51 0C 58
							39 00 00 03 51 0C 59
							39 00 00 03 51 0C 5A
							39 00 00 03 51 0C 5B
							39 00 00 03 51 0C 5C
							39 00 00 03 51 0C 5D
							39 00 00 03 51 0C 5E
							39 00 00 03 51 0C 5F
							39 00 00 03 51 0C 60
							39 00 00 03 51 0C 61
							39 00 00 03 51 0C 62
							39 00 00 03 51 0C 63
							39 00 00 03 51 0C 64
							39 00 00 03 51 0C 65
							39 00 00 03 51 0C 66
							39 00 00 03 51 0C 67
							39 00 00 03 51 0C 68
							39 00 00 03 51 0C 69
							39 00 00 03 51 0C 6A
							39 00 00 03 51 0C 6B
							39 00 00 03 51 0C 6C
							39 00 00 03 51 0C 6D
							39 00 00 03 51 0C 6E
							39 00 00 03 51 0C 6F
							39 00 00 03 51 0C 70
							39 00 00 03 51 0C 71
							39 00 00 03 51 0C 72
							39 00 00 03 51 0C 73
							39 00 00 03 51 0C 74
							39 00 00 03 51 0C 75
							39 00 00 03 51 0C 76
							39 00 00 03 51 0C 77
							39 00 00 03 51 0C 78
							39 00 00 03 51 0C 79
							39 00 00 03 51 0C 7A
							39 00 00 03 51 0C 7B
							39 00 00 03 51 0C 7C
							39 00 00 03 51 0C 7D
							39 00 00 03 51 0C 7E
							39 00 00 03 51 0C 7F
							39 00 00 03 51 0C 80
							39 00 00 03 51 0C 81
							39 00 00 03 51 0C 82
							39 00 00 03 51 0C 83
							39 00 00 03 51 0C 84
							39 00 00 03 51 0C 85
							39 00 00 03 51 0C 86
							39 00 00 03 51 0C 87
							39 00 00 03 51 0C 88
							39 00 00 03 51 0C 89
							39 00 00 03 51 0C 8A
							39 00 00 03 51 0C 8B
							39 00 00 03 51 0C 8C
							39 00 00 03 51 0C 8D
							39 00 00 03 51 0C 8E
							39 00 00 03 51 0C 8F
							39 00 00 03 51 0C 90
							39 00 00 03 51 0C 91
							39 00 00 03 51 0C 92
							39 00 00 03 51 0C 93
							39 00 00 03 51 0C 94
							39 00 00 03 51 0C 95
							39 00 00 03 51 0C 96
							39 00 00 03 51 0C 97
							39 00 00 03 51 0C 98
							39 00 00 03 51 0C 99
							39 00 00 03 51 0C 9A
							39 00 00 03 51 0C 9B
							39 00 00 03 51 0C 9C
							39 00 00 03 51 0C 9D
							39 00 00 03 51 0C 9E
							39 00 00 03 51 0C 9F
							39 00 00 03 51 0C A0
							39 00 00 03 51 0C A1
							39 00 00 03 51 0C A2
							39 00 00 03 51 0C A3
							39 00 00 03 51 0C A4
							39 00 00 03 51 0C A5
							39 00 00 03 51 0C A6
							39 00 00 03 51 0C A7
							39 00 00 03 51 0C A8
							39 00 00 03 51 0C A9
							39 00 00 03 51 0C AA
							39 00 00 03 51 0C AB
							39 00 00 03 51 0C AC
							39 00 00 03 51 0C AD
							39 00 00 03 51 0C AE
							39 00 00 03 51 0C AF
							39 00 00 03 51 0C B0
							39 00 00 03 51 0C B1
							39 00 00 03 51 0C B2
							39 00 00 03 51 0C B3
							39 00 00 03 51 0C B4
							39 00 00 03 51 0C B5
							39 00 00 03 51 0C B6
							39 00 00 03 51 0C B7
							39 00 00 03 51 0C B8
							39 00 00 03 51 0C B9
							39 00 00 03 51 0C BA
							39 00 00 03 51 0C BB
							39 00 00 03 51 0C BC
							39 00 00 03 51 0C BD
							39 00 00 03 51 0C BE
							39 00 00 03 51 0C BF
							39 00 00 03 51 0C C0
							39 00 00 03 51 0C C1
							39 00 00 03 51 0C C2
							39 00 00 03 51 0C C3
							39 00 00 03 51 0C C4
							39 00 00 03 51 0C C5
							39 00 00 03 51 0C C6
							39 00 00 03 51 0C C7
							39 00 00 03 51 0C C8
							39 00 00 03 51 0C C9
							39 00 00 03 51 0C CA
							39 00 00 03 51 0C CB
							39 00 00 03 51 0C CC
							39 00 00 03 51 0C CD
							39 00 00 03 51 0C CE
							39 00 00 03 51 0C CF
							39 00 00 03 51 0C D0
							39 00 00 03 51 0C D1
							39 00 00 03 51 0C D2
							39 00 00 03 51 0C D3
							39 00 00 03 51 0C D4
							39 00 00 03 51 0C D5
							39 00 00 03 51 0C D6
							39 00 00 03 51 0C D7
							39 00 00 03 51 0C D8
							39 00 00 03 51 0C D9
							39 00 00 03 51 0C DA
							39 00 00 03 51 0C DB
							39 00 00 03 51 0C DC
							39 00 00 03 51 0C DD
							39 00 00 03 51 0C DE
							39 00 00 03 51 0C DF
							39 00 00 03 51 0C E0
							39 00 00 03 51 0C E1
							39 00 00 03 51 0C E2
							39 00 00 03 51 0C E3
							39 00 00 03 51 0C E4
							39 00 00 03 51 0C E5
							39 00 00 03 51 0C E6
							39 00 00 03 51 0C E7
							39 00 00 03 51 0C E8
							39 00 00 03 51 0C E9
							39 00 00 03 51 0C EA
							39 00 00 03 51 0C EB
							39 00 00 03 51 0C EC
							39 00 00 03 51 0C ED
							39 00 00 03 51 0C EE
							39 00 00 03 51 0C EF
							39 00 00 03 51 0C F0
							39 00 00 03 51 0C F1
							39 00 00 03 51 0C F2
							39 00 00 03 51 0C F3
							39 00 00 03 51 0C F4
							39 00 00 03 51 0C F5
							39 00 00 03 51 0C F6
							39 00 00 03 51 0C F7
							39 00 00 03 51 0C F8
							39 00 00 03 51 0C F9
							39 00 00 03 51 0C FA
							39 00 00 03 51 0C FB
							39 00 00 03 51 0C FC
							39 00 00 03 51 0C FD
							39 00 00 03 51 0C FE
							39 00 00 03 51 0C FF
							39 00 00 03 51 0D 00
							39 00 00 03 51 0D 01
							39 00 00 03 51 0D 02
							39 00 00 03 51 0D 03
							39 00 00 03 51 0D 04
							39 00 00 03 51 0D 05
							39 00 00 03 51 0D 06
							39 00 00 03 51 0D 07
							39 00 00 03 51 0D 08
							39 00 00 03 51 0D 09
							39 00 00 03 51 0D 0A
							39 00 00 03 51 0D 0B
							39 00 00 03 51 0D 0C
							39 00 00 03 51 0D 0D
							39 00 00 03 51 0D 0E
							39 00 00 03 51 0D 0F
							39 00 00 03 51 0D 10
							39 00 00 03 51 0D 11
							39 00 00 03 51 0D 12
							39 00 00 03 51 0D 13
							39 00 00 03 51 0D 14
							39 00 00 03 51 0D 15
							39 00 00 03 51 0D 16
							39 00 00 03 51 0D 17
							39 00 00 03 51 0D 18
							39 00 00 03 51 0D 19
							39 00 00 03 51 0D 1A
							39 00 00 03 51 0D 1B
							39 00 00 03 51 0D 1C
							39 00 00 03 51 0D 1D
							39 00 00 03 51 0D 1E
							39 00 00 03 51 0D 1F
							39 00 00 03 51 0D 20
							39 00 00 03 51 0D 21
							39 00 00 03 51 0D 22
							39 00 00 03 51 0D 23
							39 00 00 03 51 0D 24
							39 00 00 03 51 0D 25
							39 00 00 03 51 0D 26
							39 00 00 03 51 0D 27
							39 00 00 03 51 0D 28
							39 00 00 03 51 0D 29
							39 00 00 03 51 0D 2A
							39 00 00 03 51 0D 2B
							39 00 00 03 51 0D 2C
							39 00 00 03 51 0D 2D
							39 00 00 03 51 0D 2E
							39 00 00 03 51 0D 2F
							39 00 00 03 51 0D 30
							39 00 00 03 51 0D 31
							39 00 00 03 51 0D 32
							39 00 00 03 51 0D 33
							39 00 00 03 51 0D 34
							39 00 00 03 51 0D 35
							39 00 00 03 51 0D 36
							39 00 00 03 51 0D 37
							39 00 00 03 51 0D 38
							39 00 00 03 51 0D 39
							39 00 00 03 51 0D 3A
							39 00 00 03 51 0D 3B
							39 00 00 03 51 0D 3C
							39 00 00 03 51 0D 3D
							39 00 00 03 51 0D 3E
							39 00 00 03 51 0D 3F
							39 00 00 03 51 0D 40
							39 00 00 03 51 0D 41
							39 00 00 03 51 0D 42
							39 00 00 03 51 0D 43
							39 00 00 03 51 0D 44
							39 00 00 03 51 0D 45
							39 00 00 03 51 0D 46
							39 00 00 03 51 0D 47
							39 00 00 03 51 0D 48
							39 00 00 03 51 0D 49
							39 00 00 03 51 0D 4A
							39 00 00 03 51 0D 4B
							39 00 00 03 51 0D 4C
							39 00 00 03 51 0D 4D
							39 00 00 03 51 0D 4E
							39 00 00 03 51 0D 4F
							39 00 00 03 51 0D 50
							39 00 00 03 51 0D 51
							39 00 00 03 51 0D 52
							39 00 00 03 51 0D 53
							39 00 00 03 51 0D 54
							39 00 00 03 51 0D 55
							39 00 00 03 51 0D 56
							39 00 00 03 51 0D 57
							39 00 00 03 51 0D 58
							39 00 00 03 51 0D 59
							39 00 00 03 51 0D 5A
							39 00 00 03 51 0D 5B
							39 00 00 03 51 0D 5C
							39 00 00 03 51 0D 5D
							39 00 00 03 51 0D 5E
							39 00 00 03 51 0D 5F
							39 00 00 03 51 0D 60
							39 00 00 03 51 0D 61
							39 00 00 03 51 0D 62
							39 00 00 03 51 0D 63
							39 00 00 03 51 0D 64
							39 00 00 03 51 0D 65
							39 00 00 03 51 0D 66
							39 00 00 03 51 0D 67
							39 00 00 03 51 0D 68
							39 00 00 03 51 0D 69
							39 00 00 03 51 0D 6A
							39 00 00 03 51 0D 6B
							39 00 00 03 51 0D 6C
							39 00 00 03 51 0D 6D
							39 00 00 03 51 0D 6E
							39 00 00 03 51 0D 6F
							39 00 00 03 51 0D 70
							39 00 00 03 51 0D 71
							39 00 00 03 51 0D 72
							39 00 00 03 51 0D 73
							39 00 00 03 51 0D 74
							39 00 00 03 51 0D 75
							39 00 00 03 51 0D 76
							39 00 00 03 51 0D 77
							39 00 00 03 51 0D 78
							39 00 00 03 51 0D 79
							39 00 00 03 51 0D 7A
							39 00 00 03 51 0D 7B
							39 00 00 03 51 0D 7C
							39 00 00 03 51 0D 7D
							39 00 00 03 51 0D 7E
							39 00 00 03 51 0D 7F
							39 00 00 03 51 0D 80
							39 00 00 03 51 0D 81
							39 00 00 03 51 0D 82
							39 00 00 03 51 0D 83
							39 00 00 03 51 0D 84
							39 00 00 03 51 0D 85
							39 00 00 03 51 0D 86
							39 00 00 03 51 0D 87
							39 00 00 03 51 0D 88
							39 00 00 03 51 0D 89
							39 00 00 03 51 0D 8A
							39 00 00 03 51 0D 8B
							39 00 00 03 51 0D 8C
							39 00 00 03 51 0D 8D
							39 00 00 03 51 0D 8E
							39 00 00 03 51 0D 8F
							39 00 00 03 51 0D 90
							39 00 00 03 51 0D 91
							39 00 00 03 51 0D 92
							39 00 00 03 51 0D 93
							39 00 00 03 51 0D 94
							39 00 00 03 51 0D 95
							39 00 00 03 51 0D 96
							39 00 00 03 51 0D 97
							39 00 00 03 51 0D 98
							39 00 00 03 51 0D 99
							39 00 00 03 51 0D 9A
							39 00 00 03 51 0D 9B
							39 00 00 03 51 0D 9C
							39 00 00 03 51 0D 9D
							39 00 00 03 51 0D 9E
							39 00 00 03 51 0D 9F
							39 00 00 03 51 0D A0
							39 00 00 03 51 0D A1
							39 00 00 03 51 0D A2
							39 00 00 03 51 0D A3
							39 00 00 03 51 0D A4
							39 00 00 03 51 0D A5
							39 00 00 03 51 0D A6
							39 00 00 03 51 0D A7
							39 00 00 03 51 0D A8
							39 00 00 03 51 0D A9
							39 00 00 03 51 0D AA
							39 00 00 03 51 0D AB
							39 00 00 03 51 0D AC
							39 00 00 03 51 0D AD
							39 00 00 03 51 0D AE
							39 00 00 03 51 0D AF
							39 00 00 03 51 0D B0
							39 00 00 03 51 0D B1
							39 00 00 03 51 0D B2
							39 00 00 03 51 0D B3
							39 00 00 03 51 0D B4
							39 00 00 03 51 0D B5
							39 00 00 03 51 0D B6
							39 00 00 03 51 0D B7
							39 00 00 03 51 0D B8
							39 00 00 03 51 0D B9
							39 00 00 03 51 0D BA
							39 00 00 03 51 0D BB
							39 00 00 03 51 0D BC
							39 00 00 03 51 0D BD
							39 00 00 03 51 0D BE
							39 00 00 03 51 0D BF
							39 00 00 03 51 0D C0
							39 00 00 03 51 0D C1
							39 00 00 03 51 0D C2
							39 00 00 03 51 0D C3
							39 00 00 03 51 0D C4
							39 00 00 03 51 0D C5
							39 00 00 03 51 0D C6
							39 00 00 03 51 0D C7
							39 00 00 03 51 0D C8
							39 00 00 03 51 0D C9
							39 00 00 03 51 0D CA
							39 00 00 03 51 0D CB
							39 00 00 03 51 0D CC
							39 00 00 03 51 0D CD
							39 00 00 03 51 0D CE
							39 00 00 03 51 0D CF
							39 00 00 03 51 0D D0
							39 00 00 03 51 0D D1
							39 00 00 03 51 0D D2
							39 00 00 03 51 0D D3
							39 00 00 03 51 0D D4
							39 00 00 03 51 0D D5
							39 00 00 03 51 0D D6
							39 00 00 03 51 0D D7
							39 00 00 03 51 0D D8
							39 00 00 03 51 0D D9
							39 00 00 03 51 0D DA
							39 00 00 03 51 0D DB
							39 00 00 03 51 0D DC
							39 00 00 03 51 0D DD
							39 00 00 03 51 0D DE
							39 00 00 03 51 0D DF
							39 00 00 03 51 0D E0
							39 00 00 03 51 0D E1
							39 00 00 03 51 0D E2
							39 00 00 03 51 0D E3
							39 00 00 03 51 0D E4
							39 00 00 03 51 0D E5
							39 00 00 03 51 0D E6
							39 00 00 03 51 0D E7
							39 00 00 03 51 0D E8
							39 00 00 03 51 0D E9
							39 00 00 03 51 0D EA
							39 00 00 03 51 0D EB
							39 00 00 03 51 0D EC
							39 00 00 03 51 0D ED
							39 00 00 03 51 0D EE
							39 00 00 03 51 0D EF
							39 00 00 03 51 0D F0
							39 00 00 03 51 0D F1
							39 00 00 03 51 0D F2
							39 00 00 03 51 0D F3
							39 00 00 03 51 0D F4
							39 00 00 03 51 0D F5
							39 00 00 03 51 0D F6
							39 00 00 03 51 0D F7
							39 00 00 03 51 0D F8
							39 00 00 03 51 0D F9
							39 00 00 03 51 0D FA
							39 00 00 03 51 0D FB
							39 00 00 03 51 0D FC
							39 00 00 03 51 0D FD
							39 00 00 03 51 0D FE
							39 00 00 03 51 0D FF
							39 00 00 03 51 0E 00
							39 00 00 03 51 0E 01
							39 00 00 03 51 0E 02
							39 00 00 03 51 0E 03
							39 00 00 03 51 0E 04
							39 00 00 03 51 0E 05
							39 00 00 03 51 0E 06
							39 00 00 03 51 0E 07
							39 00 00 03 51 0E 08
							39 00 00 03 51 0E 09
							39 00 00 03 51 0E 0A
							39 00 00 03 51 0E 0B
							39 00 00 03 51 0E 0C
							39 00 00 03 51 0E 0D
							39 00 00 03 51 0E 0E
							39 00 00 03 51 0E 0F
							39 00 00 03 51 0E 10
							39 00 00 03 51 0E 11
							39 00 00 03 51 0E 12
							39 00 00 03 51 0E 13
							39 00 00 03 51 0E 14
							39 00 00 03 51 0E 15
							39 00 00 03 51 0E 16
							39 00 00 03 51 0E 17
							39 00 00 03 51 0E 18
							39 00 00 03 51 0E 19
							39 00 00 03 51 0E 1A
							39 00 00 03 51 0E 1B
							39 00 00 03 51 0E 1C
							39 00 00 03 51 0E 1D
							39 00 00 03 51 0E 1E
							39 00 00 03 51 0E 1F
							39 00 00 03 51 0E 20
							39 00 00 03 51 0E 21
							39 00 00 03 51 0E 22
							39 00 00 03 51 0E 23
							39 00 00 03 51 0E 24
							39 00 00 03 51 0E 25
							39 00 00 03 51 0E 26
							39 00 00 03 51 0E 27
							39 00 00 03 51 0E 28
							39 00 00 03 51 0E 29
							39 00 00 03 51 0E 2A
							39 00 00 03 51 0E 2B
							39 00 00 03 51 0E 2C
							39 00 00 03 51 0E 2D
							39 00 00 03 51 0E 2E
							39 00 00 03 51 0E 2F
							39 00 00 03 51 0E 30
							39 00 00 03 51 0E 31
							39 00 00 03 51 0E 32
							39 00 00 03 51 0E 33
							39 00 00 03 51 0E 34
							39 00 00 03 51 0E 35
							39 00 00 03 51 0E 36
							39 00 00 03 51 0E 37
							39 00 00 03 51 0E 38
							39 00 00 03 51 0E 39
							39 00 00 03 51 0E 3A
							39 00 00 03 51 0E 3B
							39 00 00 03 51 0E 3C
							39 00 00 03 51 0E 3D
							39 00 00 03 51 0E 3E
							39 00 00 03 51 0E 3F
							39 00 00 03 51 0E 40
							39 00 00 03 51 0E 41
							39 00 00 03 51 0E 42
							39 00 00 03 51 0E 43
							39 00 00 03 51 0E 44
							39 00 00 03 51 0E 45
							39 00 00 03 51 0E 46
							39 00 00 03 51 0E 47
							39 00 00 03 51 0E 48
							39 00 00 03 51 0E 49
							39 00 00 03 51 0E 4A
							39 00 00 03 51 0E 4B
							39 00 00 03 51 0E 4C
							39 00 00 03 51 0E 4D
							39 00 00 03 51 0E 4E
							39 00 00 03 51 0E 4F
							39 00 00 03 51 0E 50
							39 00 00 03 51 0E 51
							39 00 00 03 51 0E 52
							39 00 00 03 51 0E 53
							39 00 00 03 51 0E 54
							39 00 00 03 51 0E 55
							39 00 00 03 51 0E 56
							39 00 00 03 51 0E 57
							39 00 00 03 51 0E 58
							39 00 00 03 51 0E 59
							39 00 00 03 51 0E 5A
							39 00 00 03 51 0E 5B
							39 00 00 03 51 0E 5C
							39 00 00 03 51 0E 5D
							39 00 00 03 51 0E 5E
							39 00 00 03 51 0E 5F
							39 00 00 03 51 0E 60
							39 00 00 03 51 0E 61
							39 00 00 03 51 0E 62
							39 00 00 03 51 0E 63
							39 00 00 03 51 0E 64
							39 00 00 03 51 0E 65
							39 00 00 03 51 0E 66
							39 00 00 03 51 0E 67
							39 00 00 03 51 0E 68
							39 00 00 03 51 0E 69
							39 00 00 03 51 0E 6A
							39 00 00 03 51 0E 6B
							39 00 00 03 51 0E 6C
							39 00 00 03 51 0E 6D
							39 00 00 03 51 0E 6E
							39 00 00 03 51 0E 6F
							39 00 00 03 51 0E 70
							39 00 00 03 51 0E 71
							39 00 00 03 51 0E 72
							39 00 00 03 51 0E 73
							39 00 00 03 51 0E 74
							39 00 00 03 51 0E 75
							39 00 00 03 51 0E 76
							39 00 00 03 51 0E 77
							39 00 00 03 51 0E 78
							39 00 00 03 51 0E 79
							39 00 00 03 51 0E 7A
							39 00 00 03 51 0E 7B
							39 00 00 03 51 0E 7C
							39 00 00 03 51 0E 7D
							39 00 00 03 51 0E 7E
							39 00 00 03 51 0E 7F
							39 00 00 03 51 0E 80
							39 00 00 03 51 0E 81
							39 00 00 03 51 0E 82
							39 00 00 03 51 0E 83
							39 00 00 03 51 0E 84
							39 00 00 03 51 0E 85
							39 00 00 03 51 0E 86
							39 00 00 03 51 0E 87
							39 00 00 03 51 0E 88
							39 00 00 03 51 0E 89
							39 00 00 03 51 0E 8A
							39 00 00 03 51 0E 8B
							39 00 00 03 51 0E 8C
							39 00 00 03 51 0E 8D
							39 00 00 03 51 0E 8E
							39 00 00 03 51 0E 8F
							39 00 00 03 51 0E 90
							39 00 00 03 51 0E 91
							39 00 00 03 51 0E 92
							39 00 00 03 51 0E 93
							39 00 00 03 51 0E 94
							39 00 00 03 51 0E 95
							39 00 00 03 51 0E 96
							39 00 00 03 51 0E 97
							39 00 00 03 51 0E 98
							39 00 00 03 51 0E 99
							39 00 00 03 51 0E 9A
							39 00 00 03 51 0E 9B
							39 00 00 03 51 0E 9C
							39 00 00 03 51 0E 9D
							39 00 00 03 51 0E 9E
							39 00 00 03 51 0E 9F
							39 00 00 03 51 0E A0
							39 00 00 03 51 0E A1
							39 00 00 03 51 0E A2
							39 00 00 03 51 0E A3
							39 00 00 03 51 0E A4
							39 00 00 03 51 0E A5
							39 00 00 03 51 0E A6
							39 00 00 03 51 0E A7
							39 00 00 03 51 0E A8
							39 00 00 03 51 0E A9
							39 00 00 03 51 0E AA
							39 00 00 03 51 0E AB
							39 00 00 03 51 0E AC
							39 00 00 03 51 0E AD
							39 00 00 03 51 0E AE
							39 00 00 03 51 0E AF
							39 00 00 03 51 0E B0
							39 00 00 03 51 0E B1
							39 00 00 03 51 0E B2
							39 00 00 03 51 0E B3
							39 00 00 03 51 0E B4
							39 00 00 03 51 0E B5
							39 00 00 03 51 0E B6
							39 00 00 03 51 0E B7
							39 00 00 03 51 0E B8
							39 00 00 03 51 0E B9
							39 00 00 03 51 0E BA
							39 00 00 03 51 0E BB
							39 00 00 03 51 0E BC
							39 00 00 03 51 0E BD
							39 00 00 03 51 0E BE
							39 00 00 03 51 0E BF
							39 00 00 03 51 0E C0
							39 00 00 03 51 0E C1
							39 00 00 03 51 0E C2
							39 00 00 03 51 0E C3
							39 00 00 03 51 0E C4
							39 00 00 03 51 0E C5
							39 00 00 03 51 0E C6
							39 00 00 03 51 0E C7
							39 00 00 03 51 0E C8
							39 00 00 03 51 0E C9
							39 00 00 03 51 0E CA
							39 00 00 03 51 0E CB
							39 00 00 03 51 0E CC
							39 00 00 03 51 0E CD
							39 00 00 03 51 0E CE
							39 00 00 03 51 0E CF
							39 00 00 03 51 0E D0
							39 00 00 03 51 0E D1
							39 00 00 03 51 0E D2
							39 00 00 03 51 0E D3
							39 00 00 03 51 0E D4
							39 00 00 03 51 0E D5
							39 00 00 03 51 0E D6
							39 00 00 03 51 0E D7
							39 00 00 03 51 0E D8
							39 00 00 03 51 0E D9
							39 00 00 03 51 0E DA
							39 00 00 03 51 0E DB
							39 00 00 03 51 0E DC
							39 00 00 03 51 0E DD
							39 00 00 03 51 0E DE
							39 00 00 03 51 0E DF
							39 00 00 03 51 0E E0
							39 00 00 03 51 0E E1
							39 00 00 03 51 0E E2
							39 00 00 03 51 0E E3
							39 00 00 03 51 0E E4
							39 00 00 03 51 0E E5
							39 00 00 03 51 0E E6
							39 00 00 03 51 0E E7
							39 00 00 03 51 0E E8
							39 00 00 03 51 0E E9
							39 00 00 03 51 0E EA
							39 00 00 03 51 0E EB
							39 00 00 03 51 0E EC
							39 00 00 03 51 0E ED
							39 00 00 03 51 0E EE
							39 00 00 03 51 0E EF
							39 00 00 03 51 0E F0
							39 00 00 03 51 0E F1
							39 00 00 03 51 0E F2
							39 00 00 03 51 0E F3
							39 00 00 03 51 0E F4
							39 00 00 03 51 0E F5
							39 00 00 03 51 0E F6
							39 00 00 03 51 0E F7
							39 00 00 03 51 0E F8
							39 00 00 03 51 0E F9
							39 00 00 03 51 0E FA
							39 00 00 03 51 0E FB
							39 00 00 03 51 0E FC
							39 00 00 03 51 0E FD
							39 00 00 03 51 0E FE
							39 00 00 03 51 0E FF
							39 00 00 03 51 0F 00
							39 00 00 03 51 0F 01
							39 00 00 03 51 0F 02
							39 00 00 03 51 0F 03
							39 00 00 03 51 0F 04
							39 00 00 03 51 0F 05
							39 00 00 03 51 0F 06
							39 00 00 03 51 0F 07
							39 00 00 03 51 0F 08
							39 00 00 03 51 0F 09
							39 00 00 03 51 0F 0A
							39 00 00 03 51 0F 0B
							39 00 00 03 51 0F 0C
							39 00 00 03 51 0F 0D
							39 00 00 03 51 0F 0E
							39 00 00 03 51 0F 0F
							39 00 00 03 51 0F 10
							39 00 00 03 51 0F 11
							39 00 00 03 51 0F 12
							39 00 00 03 51 0F 13
							39 00 00 03 51 0F 14
							39 00 00 03 51 0F 15
							39 00 00 03 51 0F 16
							39 00 00 03 51 0F 17
							39 00 00 03 51 0F 18
							39 00 00 03 51 0F 19
							39 00 00 03 51 0F 1A
							39 00 00 03 51 0F 1B
							39 00 00 03 51 0F 1C
							39 00 00 03 51 0F 1D
							39 00 00 03 51 0F 1E
							39 00 00 03 51 0F 1F
							39 00 00 03 51 0F 20
							39 00 00 03 51 0F 21
							39 00 00 03 51 0F 22
							39 00 00 03 51 0F 23
							39 00 00 03 51 0F 24
							39 00 00 03 51 0F 25
							39 00 00 03 51 0F 26
							39 00 00 03 51 0F 27
							39 00 00 03 51 0F 28
							39 00 00 03 51 0F 29
							39 00 00 03 51 0F 2A
							39 00 00 03 51 0F 2B
							39 00 00 03 51 0F 2C
							39 00 00 03 51 0F 2D
							39 00 00 03 51 0F 2E
							39 00 00 03 51 0F 2F
							39 00 00 03 51 0F 30
							39 00 00 03 51 0F 31
							39 00 00 03 51 0F 32
							39 00 00 03 51 0F 33
							39 00 00 03 51 0F 34
							39 00 00 03 51 0F 35
							39 00 00 03 51 0F 36
							39 00 00 03 51 0F 37
							39 00 00 03 51 0F 38
							39 00 00 03 51 0F 39
							39 00 00 03 51 0F 3A
							39 00 00 03 51 0F 3B
							39 00 00 03 51 0F 3C
							39 00 00 03 51 0F 3D
							39 00 00 03 51 0F 3E
							39 00 00 03 51 0F 3F
							39 00 00 03 51 0F 40
							39 00 00 03 51 0F 41
							39 00 00 03 51 0F 42
							39 00 00 03 51 0F 43
							39 00 00 03 51 0F 44
							39 00 00 03 51 0F 45
							39 00 00 03 51 0F 46
							39 00 00 03 51 0F 47
							39 00 00 03 51 0F 48
							39 00 00 03 51 0F 49
							39 00 00 03 51 0F 4A
							39 00 00 03 51 0F 4B
							39 00 00 03 51 0F 4C
							39 00 00 03 51 0F 4D
							39 00 00 03 51 0F 4E
							39 00 00 03 51 0F 4F
							39 00 00 03 51 0F 50
							39 00 00 03 51 0F 51
							39 00 00 03 51 0F 52
							39 00 00 03 51 0F 53
							39 00 00 03 51 0F 54
							39 00 00 03 51 0F 55
							39 00 00 03 51 0F 56
							39 00 00 03 51 0F 57
							39 00 00 03 51 0F 58
							39 00 00 03 51 0F 59
							39 00 00 03 51 0F 5A
							39 00 00 03 51 0F 5B
							39 00 00 03 51 0F 5C
							39 00 00 03 51 0F 5D
							39 00 00 03 51 0F 5E
							39 00 00 03 51 0F 5F
							39 00 00 03 51 0F 60
							39 00 00 03 51 0F 61
							39 00 00 03 51 0F 62
							39 00 00 03 51 0F 63
							39 00 00 03 51 0F 64
							39 00 00 03 51 0F 65
							39 00 00 03 51 0F 66
							39 00 00 03 51 0F 67
							39 00 00 03 51 0F 68
							39 00 00 03 51 0F 69
							39 00 00 03 51 0F 6A
							39 00 00 03 51 0F 6B
							39 00 00 03 51 0F 6C
							39 00 00 03 51 0F 6D
							39 00 00 03 51 0F 6E
							39 00 00 03 51 0F 6F
							39 00 00 03 51 0F 70
							39 00 00 03 51 0F 71
							39 00 00 03 51 0F 72
							39 00 00 03 51 0F 73
							39 00 00 03 51 0F 74
							39 00 00 03 51 0F 75
							39 00 00 03 51 0F 76
							39 00 00 03 51 0F 77
							39 00 00 03 51 0F 78
							39 00 00 03 51 0F 79
							39 00 00 03 51 0F 7A
							39 00 00 03 51 0F 7B
							39 00 00 03 51 0F 7C
							39 00 00 03 51 0F 7D
							39 00 00 03 51 0F 7E
							39 00 00 03 51 0F 7F
							39 00 00 03 51 0F 80
							39 00 00 03 51 0F 81
							39 00 00 03 51 0F 82
							39 00 00 03 51 0F 83
							39 00 00 03 51 0F 84
							39 00 00 03 51 0F 85
							39 00 00 03 51 0F 86
							39 00 00 03 51 0F 87
							39 00 00 03 51 0F 88
							39 00 00 03 51 0F 89
							39 00 00 03 51 0F 8A
							39 00 00 03 51 0F 8B
							39 00 00 03 51 0F 8C
							39 00 00 03 51 0F 8D
							39 00 00 03 51 0F 8E
							39 00 00 03 51 0F 8F
							39 00 00 03 51 0F 90
							39 00 00 03 51 0F 91
							39 00 00 03 51 0F 92
							39 00 00 03 51 0F 93
							39 00 00 03 51 0F 94
							39 00 00 03 51 0F 95
							39 00 00 03 51 0F 96
							39 00 00 03 51 0F 97
							39 00 00 03 51 0F 98
							39 00 00 03 51 0F 99
							39 00 00 03 51 0F 9A
							39 00 00 03 51 0F 9B
							39 00 00 03 51 0F 9C
							39 00 00 03 51 0F 9D
							39 00 00 03 51 0F 9E
							39 00 00 03 51 0F 9F
							39 00 00 03 51 0F A0
							39 00 00 03 51 0F A1
							39 00 00 03 51 0F A2
							39 00 00 03 51 0F A3
							39 00 00 03 51 0F A4
							39 00 00 03 51 0F A5
							39 00 00 03 51 0F A6
							39 00 00 03 51 0F A7
							39 00 00 03 51 0F A8
							39 00 00 03 51 0F A9
							39 00 00 03 51 0F AA
							39 00 00 03 51 0F AB
							39 00 00 03 51 0F AC
							39 00 00 03 51 0F AD
							39 00 00 03 51 0F AE
							39 00 00 03 51 0F AF
							39 00 00 03 51 0F B0
							39 00 00 03 51 0F B1
							39 00 00 03 51 0F B2
							39 00 00 03 51 0F B3
							39 00 00 03 51 0F B4
							39 00 00 03 51 0F B5
							39 00 00 03 51 0F B6
							39 00 00 03 51 0F B7
							39 00 00 03 51 0F B8
							39 00 00 03 51 0F B9
							39 00 00 03 51 0F BA
							39 00 00 03 51 0F BB
							39 00 00 03 51 0F BC
							39 00 00 03 51 0F BD
							39 00 00 03 51 0F BE
							39 00 00 03 51 0F BF
							39 00 00 03 51 0F C0
							39 00 00 03 51 0F C1
							39 00 00 03 51 0F C2
							39 00 00 03 51 0F C3
							39 00 00 03 51 0F C4
							39 00 00 03 51 0F C5
							39 00 00 03 51 0F C6
							39 00 00 03 51 0F C7
							39 00 00 03 51 0F C8
							39 00 00 03 51 0F C9
							39 00 00 03 51 0F CA
							39 00 00 03 51 0F CB
							39 00 00 03 51 0F CC
							39 00 00 03 51 0F CD
							39 00 00 03 51 0F CE
							39 00 00 03 51 0F CF
							39 00 00 03 51 0F D0
							39 00 00 03 51 0F D1
							39 00 00 03 51 0F D2
							39 00 00 03 51 0F D3
							39 00 00 03 51 0F D4
							39 00 00 03 51 0F D5
							39 00 00 03 51 0F D6
							39 00 00 03 51 0F D7
							39 00 00 03 51 0F D8
							39 00 00 03 51 0F D9
							39 00 00 03 51 0F DA
							39 00 00 03 51 0F DB
							39 00 00 03 51 0F DC
							39 00 00 03 51 0F DD
							39 00 00 03 51 0F DE
							39 00 00 03 51 0F DF
							39 00 00 03 51 0F E0
							39 00 00 03 51 0F E1
							39 00 00 03 51 0F E2
							39 00 00 03 51 0F E3
							39 00 00 03 51 0F E4
							39 00 00 03 51 0F E5
							39 00 00 03 51 0F E6
							39 00 00 03 51 0F E7
							39 00 00 03 51 0F E8
							39 00 00 03 51 0F E9
							39 00 00 03 51 0F EA
							39 00 00 03 51 0F EB
							39 00 00 03 51 0F EC
							39 00 00 03 51 0F ED
							39 00 00 03 51 0F EE
							39 00 00 03 51 0F EF
							39 00 00 03 51 0F F0
							39 00 00 03 51 0F F1
							39 00 00 03 51 0F F2
							39 00 00 03 51 0F F3
							39 00 00 03 51 0F F4
							39 00 00 03 51 0F F5
							39 00 00 03 51 0F F6
							39 00 00 03 51 0F F7
							39 00 00 03 51 0F F8
							39 00 00 03 51 0F F9
							39 00 00 03 51 0F FA
							39 00 00 03 51 0F FB
							39 00 00 03 51 0F FC
							39 00 00 03 51 0F FD
							39 00 00 03 51 0F FE
							39 00 00 03 51 0F FF
						];
					};
				};
			};
		};
	};
};
